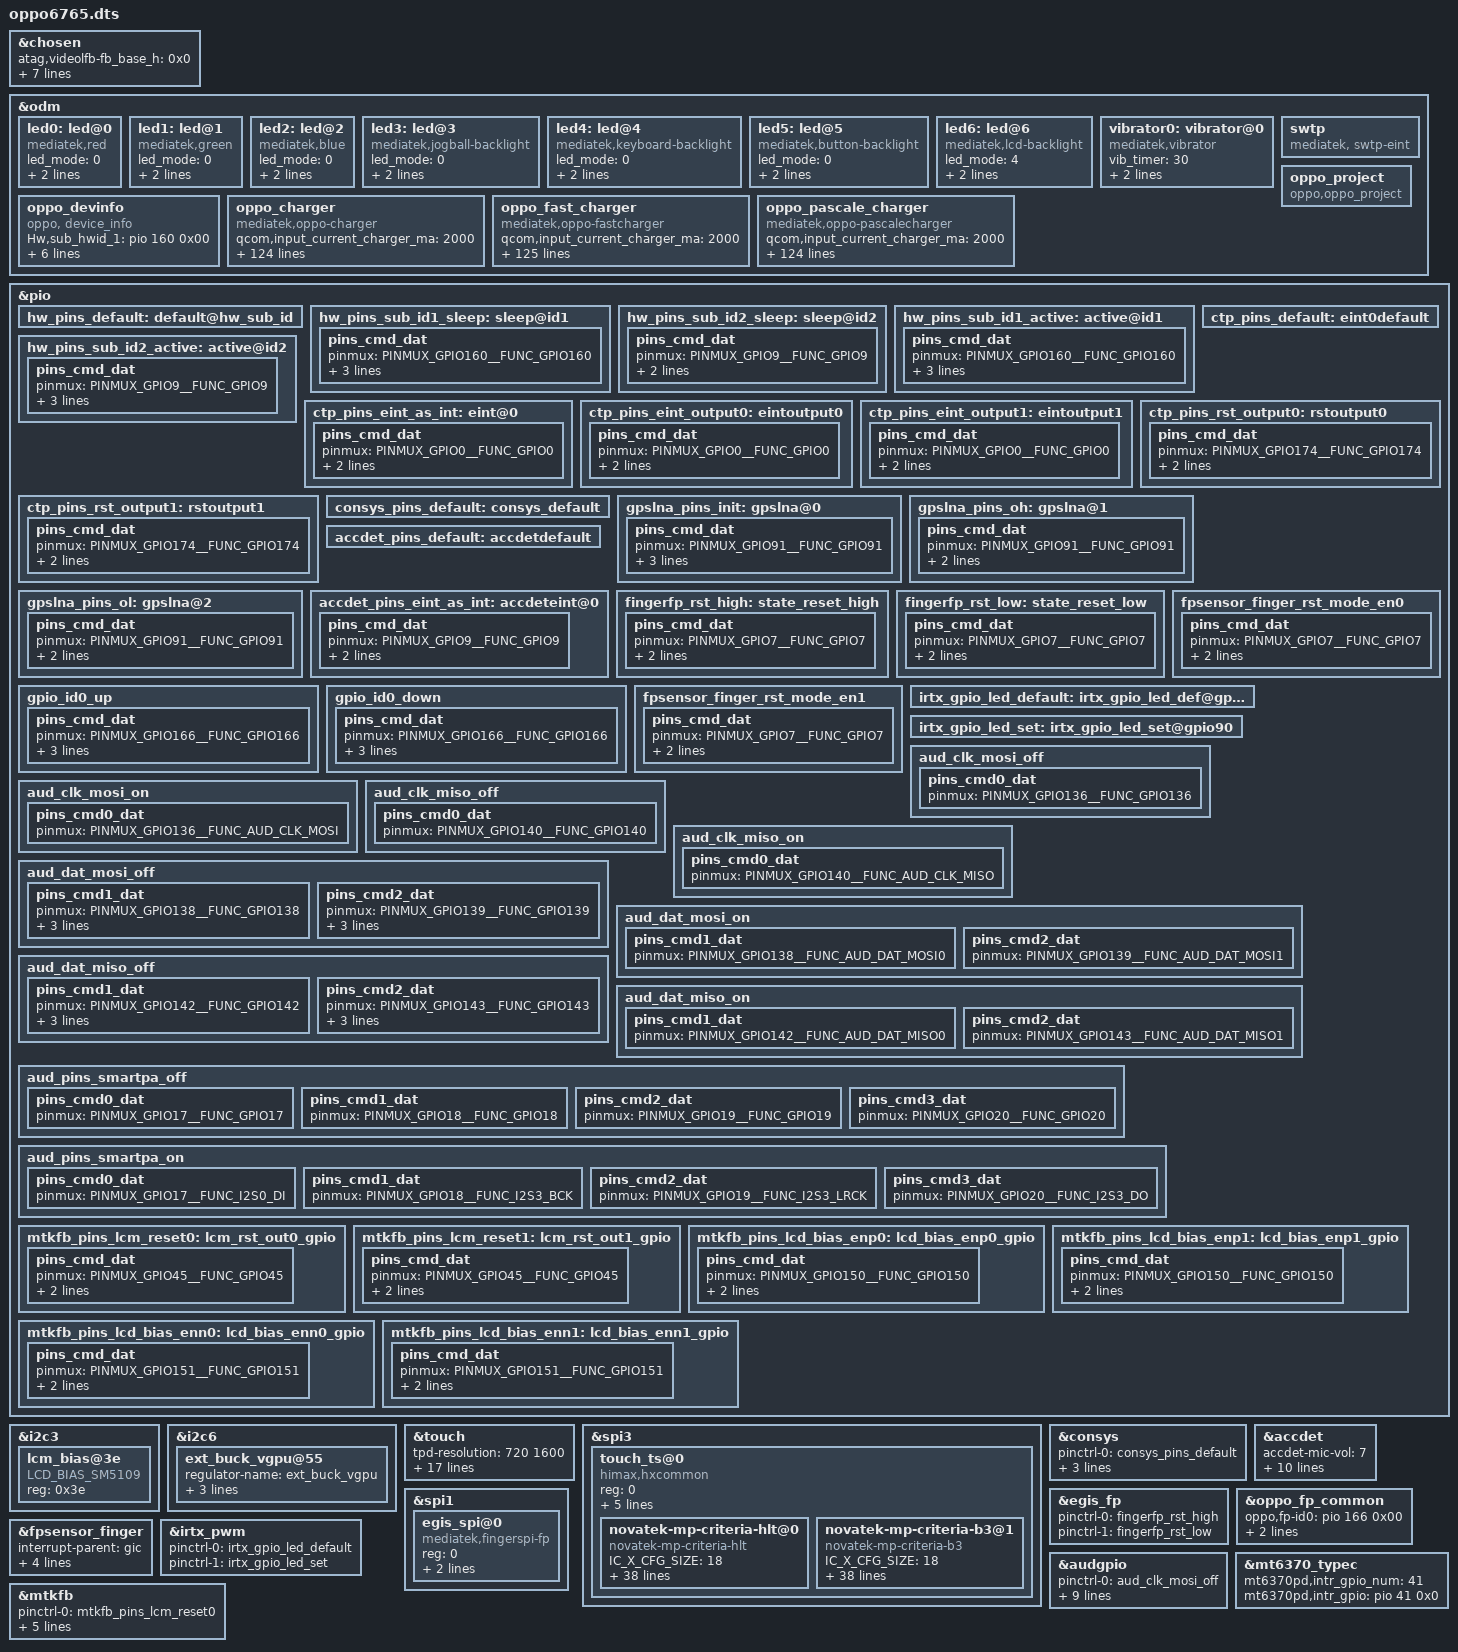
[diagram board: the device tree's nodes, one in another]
/*
 * Copyright (C) 2019 MediaTek Inc.
 *
 * This program is free software; you can redistribute it and/or modify
 * it under the terms of the GNU General Public License version 2 as
 * published by the Free Software Foundation.
 *
 * This program is distributed in the hope that it will be useful,
 * but WITHOUT ANY WARRANTY; without even the implied warranty of
 * MERCHANTABILITY or FITNESS FOR A PARTICULAR PURPOSE.
 * See http://www.gnu.org/licenses/gpl-2.0.html for more details.
 */

#include <dt-bindings/interrupt-controller/arm-gic.h>
#include <dt-bindings/interrupt-controller/irq.h>
#include <dt-bindings/pinctrl/mt6765-pinfunc.h>
#include <dt-bindings/clock/mt6765-clk.h>

/dts-v1/;
/plugin/;

/* chosen */
&chosen {

	/* fpga may has no lk, we need to specify display info here */
	/* fb buffer is reserved using this dts by memory node above */
	atag,videolfb-fb_base_h = <0x0>;
	atag,videolfb-fb_base_l = <0x5e605000>;
	atag,videolfb-islcmfound = <1>;
	/* because no lk, so lcm is not inited */
	atag,videolfb-islcm_inited = <0>;
	atag,videolfb-fps= <6000>;
	atag,videolfb-vramSize= <0x017bb000>;
	atag,videolfb-lcmname= "nt35695B_fhd_dsi_cmd_auo_rt5081_drv";
};

&odm {
	led0:led@0 {
		compatible = "mediatek,red";
		led_mode = <0>;
		data = <1>;
		pwm_config = <0 0 0 0 0>;
	};
	led1:led@1 {
		compatible = "mediatek,green";
		led_mode = <0>;
		data = <1>;
		pwm_config = <0 0 0 0 0>;
	};
	led2:led@2 {
		compatible = "mediatek,blue";
		led_mode = <0>;
		data = <1>;
		pwm_config = <0 0 0 0 0>;
	};
	led3:led@3 {
		compatible = "mediatek,jogball-backlight";
		led_mode = <0>;
		data = <1>;
		pwm_config = <0 0 0 0 0>;
	};
	led4:led@4 {
		compatible = "mediatek,keyboard-backlight";
		led_mode = <0>;
		data = <1>;
		pwm_config = <0 0 0 0 0>;
	};
	led5:led@5 {
		compatible = "mediatek,button-backlight";
		led_mode = <0>;
		data = <1>;
		pwm_config = <0 0 0 0 0>;
	};
	led6:led@6 {
		compatible = "mediatek,lcd-backlight";
		led_mode = <4>;
		data = <1>;
		pwm_config = <0 3 0 0 0>;
	};
	vibrator0:vibrator@0 {
		compatible = "mediatek,vibrator";
		/*
		vib_timer = <25>;
		vib_limit = <9>;
		vib_vol= <9>;
		*/
/* Tiancheng.Peng@ODM_WT.BSP.POWER 2020/04/09,add vibrator vol to 3V*/
		vib_timer = <30>;
		vib_limit = <0>;
		vib_vol= <11>;
	};
//#ifdef ODM_WT_EDIT
/*Xin.Kou@ODM_WT.NW.RF.swtp, 2020/04/08, Add for swtp, RF cable detect */
	swtp:swtp {
		compatible = "mediatek, swtp-eint";
	};
//#endif /*ODM_WT_EDIT*/
//#ifdef ODM_WT_EDIT
/* Haibo.Dong@ODM_WT.BSP.Storage.Emmc 2020/03/28,add oppo project framework*/
	oppo_project:oppo_project {
		compatible = "oppo,oppo_project";
	};
/* Haibo.Dong@ODM_WT.BSP.Storage.Emmc 2020/04/02,add oppo devinfo framework*/
	oppo_devinfo:oppo_devinfo {
		compatible = "oppo, device_info";
	};
//#endif /*ODM_WT_EDIT*/

//#ifdef ODM_WT_EDIT
/*Sidong.Zhao@ODM_WT.BSP.CHG 2019/11/4,add oppo charge framework*/
	oppo_charger: oppo_charger {
		compatible = "mediatek,oppo-charger";
		//pinctrl-names = "default", "charger_gpio_as_output_low", "charger_gpio_as_output_high", "ship_sleep", "ship_active", "shortc_active";
		//pinctrl-0 = <&charger_pins_default>;
		//pinctrl-1 = <&charger_pins_eint_output0>;
		//pinctrl-2 = <&charger_pins_eint_output1>;
		//pinctrl-3 = <&ship_sleep_gpio>;
		//pinctrl-4 = <&ship_active_gpio>;
		//pinctrl-5 = <&shortc_active_gpio>;

		//for oppo chg framework:
		qcom,input_current_charger_ma = <2000>;
		qcom,input_current_cdp_ma = <1500>;
		qcom,input_current_usb_ma = <500>;
		qcom,input_current_led_ma = <1200>;
		qcom,input_current_led_ma_forcmcc = <500>;
		qcom,input_current_camera_ma = <1200>;
		qcom,input_current_calling_ma = <1200>;
		
		qcom,input_current_led_ma_high = <1200>;
		qcom,input_current_led_ma_warm = <1500>;
		qcom,input_current_led_ma_normal = <2000>;

		qcom,led_high_bat_decidegc = <370>;
		qcom,led_warm_bat_decidegc = <350>;

		qcom,iterm_disabled = <0>;
		qcom,iterm_ma = <265>;
		qcom,recharge-mv = <115>;

		qcom,batt_capacity_mah = <5000>; /*typical capacity*/
		//qcom,batt_capacity_mah = <3900>; /*rated capacity*/

		qcom,removed_bat_decidegc = <190>;  /* < -19C */

		qcom,cold_bat_decidegc = <20>;  /* -2C ~ 0C */
		qcom,temp_cold_vfloat_mv = <3980>;
		qcom,temp_cold_fastchg_current_ma = <350>;

		qcom,little_cold_bat_decidegc = <0>;	/* 0C ~ 5C */
		qcom,temp_little_cold_vfloat_mv = <4435>;
		qcom,temp_little_cold_fastchg_current_ma_high = <650>;
		qcom,temp_little_cold_fastchg_current_ma_low = <650>;
		qcom,temp_little_cold_fastchg_current_ma = <650>;
		monet,temp_little_cold_usbchg_current_ma_high = <650>;
		monet,temp_little_cold_usbchg_current_ma_low = <650>;
		monet,temp_little_cold_usbchg_current_ma = <650>;

		qcom,cool_bat_decidegc = <50>;	/* 5C ~ 12C */
		qcom,temp_cool_vfloat_mv = <4435>;
		qcom,temp_cool_fastchg_current_ma_high = <1350>;
		qcom,temp_cool_fastchg_current_ma_low = <650>;
		monet,temp_cool_usbchg_current_ma_high = <650>;
		monet,temp_cool_usbchg_current_ma_low = <550>;

		qcom,little_cool_bat_decidegc = <120>;	/* 12C ~ 16C */
		qcom,temp_little_cool_vfloat_mv = <4435>;
		qcom,temp_little_cool_fastchg_current_ma = <2050>;
		monet,temp_little_cool_usbchg_current_ma = <550>;

		qcom,normal_bat_decidegc = <160>;	/* 16C ~ 45C */
		qcom,temp_normal_fastchg_current_ma = <2200>;
		monet,temp_normal_usbchg_current_ma = <550>;
		qcom,temp_normal_vfloat_mv = <4435>;

		qcom,warm_bat_decidegc = <440>;		/* 44C ~ 53C */ /*8pin Bat Vooc project need add 3 degree C*/
		qcom,temp_warm_vfloat_mv = <4130>;
		qcom,temp_warm_fastchg_current_ma = <1350>;
		monet,temp_warm_usbchg_current_ma = <550>;
		qcom,temp_warm_fastchg_current_ma_led_on = <500>;

		qcom,hot_bat_decidegc = <530>;  /* > 53C */

		qcom,non_standard_vfloat_mv = <3980>;
		qcom,non_standard_fastchg_current_ma = <512>;

		qcom,short_c_bat_cv_mv = <4330>;
		qcom,short_c_bat_vfloat_mv = <3800>;
		qcom,short_c_bat_fastchg_current_ma = <512>;
		qcom,short_c_bat_vfloat_sw_limit = <3750>;

		qcom,cold_vfloat_sw_limit = <3930>;
		qcom,little_cold_vfloat_sw_limit = <4380>;
		qcom,cool_vfloat_sw_limit = <4380>;
		qcom,little_cool_vfloat_sw_limit = <4380>;
		qcom,normal_vfloat_sw_limit = <4380>;
		qcom,warm_vfloat_sw_limit = <4080>;
		qcom,non_standard_vfloat_sw_limit = <3930>;

		qcom,max_chg_time_sec = <60000>;
		qcom,charger_hv_thr = <5800>;
		qcom,charger_recv_thr = <5800>;
		qcom,charger_lv_thr = <3400>;
		qcom,vbatt_full_thr = <4400>;
		qcom,vbatt_hv_thr = <4550>;

		qcom,vfloat_step_mv = <10>;
		qcom,non_standard_vfloat_over_sw_limit = <4000>;
		qcom,cold_vfloat_over_sw_limit = <4000>;
		qcom,little_cold_vfloat_over_sw_limit = <4450>;
		qcom,cool_vfloat_over_sw_limit = <4450>;
		qcom,little_cool_vfloat_over_sw_limit = <4450>;
		qcom,normal_vfloat_over_sw_limit = <4450>;
		qcom,warm_vfloat_over_sw_limit = <4150>;

		qcom,vbatt_power_off = <3300>;
		qcom,vbatt_soc_1 = <3410>;
		qcom,vooc_project = <0>;
		qcom,vbatt_num = <1>;

		qcom,normal_vterm_hw_inc = <150>;
		qcom,non_normal_vterm_hw_inc = <10>;

		qcom,ff1_normal_fastchg_ma = <1088>;
		qcom,ffc2_normal_fastchg_ma = <780>;/*16C~35c*/
		qcom,ffc2_temp_warm_decidegc = <350>;
		qcom,ffc2_warm_fastchg_ma = <840>;/*35C~40c*/
		qcom,ffc2_temp_high_decidegc = <400>;
		qcom,ffc2_temp_low_decidegc = <120>;
		qcom,ff1_exit_step_ma = <488>;
		qcom,ff1_warm_exit_step_ma = <418>;
		qcom,ffc2_exit_step_ma = <180>;
		qcom,ffc2_warm_exit_step_ma = <170>;

		qcom,ffc_normal_vfloat_sw_limit = <4430>;
		qcom,ffc_temp_normal_vfloat_mv = <4500>;
		qcom,ffc_normal_vfloat_over_sw_limit = <4500>;

		qcom,default_iterm_ma = <265>;
		qcom,default_temp_normal_fastchg_current_ma = <2200>;
		qcom,default_normal_vfloat_sw_limit = <4380>;
		qcom,default_temp_normal_vfloat_mv = <4435>;
		qcom,default_normal_vfloat_over_sw_limit = <4450>;

		//for 2nd chip:
		qcom,iterm_ma_2nd = <300>;
		qcom,recharge-mv_2nd = <121>;

		qcom,temp_little_cold_vfloat_mv_2nd = <4391>;	/* 0C ~ 5C */
		qcom,temp_cool_vfloat_mv_2nd = <4391>;	/* 5C ~ 12C */
		qcom,temp_little_cool_vfloat_mv_2nd = <4391>;	/* 12C ~ 16C */
		qcom,temp_normal_vfloat_mv_2nd = <4391>;	/* 16C ~ 45C */

		qcom,little_cold_vfloat_over_sw_limit_2nd = <4395>;
		qcom,cool_vfloat_over_sw_limit_2nd = <4395>;
		qcom,little_cool_vfloat_over_sw_limit_2nd = <4395>;
		qcom,normal_vfloat_over_sw_limit_2nd = <4395>;

		qcom,default_iterm_ma_2nd = <300>;
		qcom,default_temp_normal_vfloat_mv_2nd = <4391>;
		qcom,default_normal_vfloat_over_sw_limit_2nd = <4395>;

		//for control:
		//qcom,suspend_after_full;
		qcom,check_batt_full_by_sw;
		//qcom,external_gauge;
		qcom,chg_ctrl_by_calling;
		qcom,chg_ctrl_by_lcd;
		qcom,chg_ctrl_by_camera;
		qcom,sw_vfloat_over_protect_enable;
		//qcom,ffc_support;

		//GPIO config:
		//qcom,chargerid_switch-gpio = <&pio 97 0x00>;
		//qcom,ship-gpio = <&pio 155 0x00>;
		//qcom,shortc-gpio = <&pio 77 0x00>;
	};

oppo_fast_charger: oppo_fast_charger {
		compatible = "mediatek,oppo-fastcharger";
		//pinctrl-names = "default", "charger_gpio_as_output_low", "charger_gpio_as_output_high", "ship_sleep", "ship_active", "shortc_active";
		//pinctrl-0 = <&charger_pins_default>;
		//pinctrl-1 = <&charger_pins_eint_output0>;
		//pinctrl-2 = <&charger_pins_eint_output1>;
		//pinctrl-3 = <&ship_sleep_gpio>;
		//pinctrl-4 = <&ship_active_gpio>;
		//pinctrl-5 = <&shortc_active_gpio>;

		//for oppo chg framework:
		qcom,input_current_charger_ma = <2000>;
		qcom,input_current_cdp_ma = <1500>;
		qcom,input_current_usb_ma = <500>;
		qcom,input_current_led_ma = <1200>;
		qcom,input_current_led_ma_forcmcc = <500>;
		qcom,input_current_camera_ma = <1200>;
		qcom,input_current_calling_ma = <1200>;

		qcom,input_current_led_ma_high = <1000>;
		qcom,input_current_led_ma_warm = <1500>;
		qcom,input_current_led_ma_normal = <2000>;

		qcom,led_high_bat_decidegc = <370>;
		qcom,led_warm_bat_decidegc = <340>;

		qcom,iterm_disabled = <0>;
		qcom,iterm_ma = <300>;
		qcom,recharge-mv = <115>;

		qcom,batt_capacity_mah = <5000>; /*typical capacity*/
		//qcom,batt_capacity_mah = <3900>; /*rated capacity*/

		qcom,removed_bat_decidegc = <190>;  /* < -19C */

		qcom,cold_bat_decidegc = <20>;  /* -2C ~ 0C */
		qcom,temp_cold_vfloat_mv = <3980>;
		qcom,temp_cold_fastchg_current_ma = <350>;

		qcom,little_cold_bat_decidegc = <0>;	/* 0C ~ 5C */
		qcom,temp_little_cold_vfloat_mv = <4435>;
		qcom,temp_little_cold_fastchg_current_ma_high = <800>;
		qcom,temp_little_cold_fastchg_current_ma_low = <800>;
		qcom,temp_little_cold_fastchg_current_ma = <800>;
		monet,temp_little_cold_usbchg_current_ma_high = <650>;
		monet,temp_little_cold_usbchg_current_ma_low = <650>;
		monet,temp_little_cold_usbchg_current_ma = <650>;

		qcom,cool_bat_decidegc = <50>;	/* 5C ~ 12C */
		qcom,temp_cool_vfloat_mv = <4435>;
		qcom,temp_cool_fastchg_current_ma_high = <1650>;
		qcom,temp_cool_fastchg_current_ma_low = <800>;
		monet,temp_cool_usbchg_current_ma_high = <650>;
		monet,temp_cool_usbchg_current_ma_low = <550>;

		qcom,little_cool_bat_decidegc = <120>;	/* 12C ~ 16C */
		qcom,temp_little_cool_vfloat_mv = <4435>;
		qcom,temp_little_cool_fastchg_current_ma = <2050>;
		monet,temp_little_cool_usbchg_current_ma = <550>;

		qcom,normal_bat_decidegc = <160>;	/* 16C ~ 45C */
		qcom,temp_normal_fastchg_current_ma = <2200>;
		monet,temp_normal_usbchg_current_ma = <550>;
		qcom,temp_normal_vfloat_mv = <4435>;

		qcom,warm_bat_decidegc = <450>;		/* 45C ~ 53C */ /*8pin Bat Vooc project need add 3 degree C*/
		qcom,temp_warm_vfloat_mv = <4130>;
		qcom,temp_warm_fastchg_current_ma = <1650>;
		monet,temp_warm_usbchg_current_ma = <550>;
		qcom,temp_warm_fastchg_current_ma_led_on = <500>;

		qcom,hot_bat_decidegc = <530>;  /* > 53C */

		qcom,non_standard_vfloat_mv = <3980>;
		qcom,non_standard_fastchg_current_ma = <512>;

		qcom,short_c_bat_cv_mv = <4330>;
		qcom,short_c_bat_vfloat_mv = <3800>;
		qcom,short_c_bat_fastchg_current_ma = <512>;
		qcom,short_c_bat_vfloat_sw_limit = <3750>;

		qcom,cold_vfloat_sw_limit = <3930>;
		qcom,little_cold_vfloat_sw_limit = <4380>;
		qcom,cool_vfloat_sw_limit = <4380>;
		qcom,little_cool_vfloat_sw_limit = <4380>;
		qcom,normal_vfloat_sw_limit = <4380>;
		qcom,warm_vfloat_sw_limit = <4080>;
		qcom,non_standard_vfloat_sw_limit = <3930>;

		qcom,max_chg_time_sec = <72000>;
		qcom,charger_hv_thr = <9800>;
		qcom,charger_recv_thr = <9800>;
		qcom,charger_lv_thr = <3400>;
		qcom,vbatt_full_thr = <4400>;
		qcom,vbatt_hv_thr = <4550>;

		qcom,vfloat_step_mv = <10>;
		qcom,non_standard_vfloat_over_sw_limit = <4000>;
		qcom,cold_vfloat_over_sw_limit = <4000>;
		qcom,little_cold_vfloat_over_sw_limit = <4450>;
		qcom,cool_vfloat_over_sw_limit = <4450>;
		qcom,little_cool_vfloat_over_sw_limit = <4450>;
		qcom,normal_vfloat_over_sw_limit = <4450>;
		qcom,warm_vfloat_over_sw_limit = <4150>;

		qcom,vbatt_power_off = <3300>;
		qcom,vbatt_soc_1 = <3410>;
		qcom,vooc_project = <0>;
		qcom,vbatt_num = <1>;

		qcom,normal_vterm_hw_inc = <150>;
		qcom,non_normal_vterm_hw_inc = <10>;

		qcom,ff1_normal_fastchg_ma = <1088>;
		qcom,ffc2_normal_fastchg_ma = <780>;/*16C~35c*/
		qcom,ffc2_temp_warm_decidegc = <350>;
		qcom,ffc2_warm_fastchg_ma = <840>;/*35C~40c*/
		qcom,ffc2_temp_high_decidegc = <400>;
		qcom,ffc2_temp_low_decidegc = <120>;
		qcom,ff1_exit_step_ma = <488>;
		qcom,ff1_warm_exit_step_ma = <418>;
		qcom,ffc2_exit_step_ma = <180>;
		qcom,ffc2_warm_exit_step_ma = <170>;

		qcom,ffc_normal_vfloat_sw_limit = <4430>;
		qcom,ffc_temp_normal_vfloat_mv = <4500>;
		qcom,ffc_normal_vfloat_over_sw_limit = <4500>;

		qcom,default_iterm_ma = <300>;
		qcom,default_temp_normal_fastchg_current_ma = <2200>;
		qcom,default_normal_vfloat_sw_limit = <4380>;
		qcom,default_temp_normal_vfloat_mv = <4435>;
		qcom,default_normal_vfloat_over_sw_limit = <4450>;

		//for 2nd chip:
		qcom,iterm_ma_2nd = <300>;
		qcom,recharge-mv_2nd = <121>;

		qcom,temp_little_cold_vfloat_mv_2nd = <4391>;	/* 0C ~ 5C */
		qcom,temp_cool_vfloat_mv_2nd = <4391>;	/* 5C ~ 12C */
		qcom,temp_little_cool_vfloat_mv_2nd = <4391>;	/* 12C ~ 16C */
		qcom,temp_normal_vfloat_mv_2nd = <4391>;	/* 16C ~ 45C */

		qcom,little_cold_vfloat_over_sw_limit_2nd = <4395>;
		qcom,cool_vfloat_over_sw_limit_2nd = <4395>;
		qcom,little_cool_vfloat_over_sw_limit_2nd = <4395>;
		qcom,normal_vfloat_over_sw_limit_2nd = <4395>;

		qcom,default_iterm_ma_2nd = <300>;
		qcom,default_temp_normal_vfloat_mv_2nd = <4391>;
		qcom,default_normal_vfloat_over_sw_limit_2nd = <4395>;

		//for control:
		//qcom,suspend_after_full;
		qcom,check_batt_full_by_sw;
		//qcom,external_gauge;
		qcom,chg_ctrl_by_calling;
		qcom,chg_ctrl_by_lcd;
		qcom,chg_ctrl_by_camera;
		qcom,sw_vfloat_over_protect_enable;
		//qcom,ffc_support;

		//GPIO config:
		//qcom,chargerid_switch-gpio = <&pio 97 0x00>;
		//qcom,ship-gpio = <&pio 155 0x00>;
		//qcom,shortc-gpio = <&pio 77 0x00>;

		qcom,vbatt_pdqc_to_5v_thr = <4420>;
		status = "okay";
	};

oppo_pascale_charger: oppo_pascale_charger {
		compatible = "mediatek,oppo-pascalecharger";
		//pinctrl-names = "default", "charger_gpio_as_output_low", "charger_gpio_as_output_high", "ship_sleep", "ship_active", "shortc_active";
		//pinctrl-0 = <&charger_pins_default>;
		//pinctrl-1 = <&charger_pins_eint_output0>;
		//pinctrl-2 = <&charger_pins_eint_output1>;
		//pinctrl-3 = <&ship_sleep_gpio>;
		//pinctrl-4 = <&ship_active_gpio>;
		//pinctrl-5 = <&shortc_active_gpio>;

		//for oppo chg framework:
		qcom,input_current_charger_ma = <2000>;
		qcom,input_current_cdp_ma = <1500>;
		qcom,input_current_usb_ma = <500>;
		qcom,input_current_led_ma = <1200>;
		qcom,input_current_led_ma_forcmcc = <500>;
		qcom,input_current_camera_ma = <1200>;
		qcom,input_current_calling_ma = <1200>;

		qcom,input_current_led_ma_high = <1000>;
		qcom,input_current_led_ma_warm = <1500>;
		qcom,input_current_led_ma_normal = <2000>;

		qcom,led_high_bat_decidegc = <370>;
		qcom,led_warm_bat_decidegc = <340>;

		qcom,iterm_disabled = <0>;
		qcom,iterm_ma = <300>;
		qcom,recharge-mv = <115>;

		qcom,batt_capacity_mah = <6000>; /*typical capacity*/
		//qcom,batt_capacity_mah = <3900>; /*rated capacity*/

		qcom,removed_bat_decidegc = <190>;  /* < -19C */

		qcom,cold_bat_decidegc = <20>;  /* -2C ~ 0C */
		qcom,temp_cold_vfloat_mv = <3980>;
		qcom,temp_cold_fastchg_current_ma = <350>;

		qcom,little_cold_bat_decidegc = <0>;	/* 0C ~ 5C */
		qcom,temp_little_cold_vfloat_mv = <4435>;
		qcom,temp_little_cold_fastchg_current_ma_high = <800>;
		qcom,temp_little_cold_fastchg_current_ma_low = <800>;
		qcom,temp_little_cold_fastchg_current_ma = <800>;
		monet,temp_little_cold_usbchg_current_ma_high = <650>;
		monet,temp_little_cold_usbchg_current_ma_low = <650>;
		monet,temp_little_cold_usbchg_current_ma = <650>;

		qcom,cool_bat_decidegc = <50>;	/* 5C ~ 12C */
		qcom,temp_cool_vfloat_mv = <4435>;
		qcom,temp_cool_fastchg_current_ma_high = <1650>;
		qcom,temp_cool_fastchg_current_ma_low = <800>;
		monet,temp_cool_usbchg_current_ma_high = <650>;
		monet,temp_cool_usbchg_current_ma_low = <550>;

		qcom,little_cool_bat_decidegc = <120>;	/* 12C ~ 16C */
		qcom,temp_little_cool_vfloat_mv = <4435>;
		qcom,temp_little_cool_fastchg_current_ma = <2050>;
		monet,temp_little_cool_usbchg_current_ma = <550>;

		qcom,normal_bat_decidegc = <160>;	/* 16C ~ 45C */
		qcom,temp_normal_fastchg_current_ma = <2200>;
		monet,temp_normal_usbchg_current_ma = <550>;
		qcom,temp_normal_vfloat_mv = <4435>;

		qcom,warm_bat_decidegc = <450>;		/* 45C ~ 53C */ /*8pin Bat Vooc project need add 3 degree C*/
		qcom,temp_warm_vfloat_mv = <4130>;
		qcom,temp_warm_fastchg_current_ma = <1650>;
		monet,temp_warm_usbchg_current_ma = <550>;
		qcom,temp_warm_fastchg_current_ma_led_on = <500>;

		qcom,hot_bat_decidegc = <530>;  /* > 53C */

		qcom,non_standard_vfloat_mv = <3980>;
		qcom,non_standard_fastchg_current_ma = <512>;

		qcom,short_c_bat_cv_mv = <4330>;
		qcom,short_c_bat_vfloat_mv = <3800>;
		qcom,short_c_bat_fastchg_current_ma = <512>;
		qcom,short_c_bat_vfloat_sw_limit = <3750>;

		qcom,cold_vfloat_sw_limit = <3930>;
		qcom,little_cold_vfloat_sw_limit = <4380>;
		qcom,cool_vfloat_sw_limit = <4380>;
		qcom,little_cool_vfloat_sw_limit = <4380>;
		qcom,normal_vfloat_sw_limit = <4380>;
		qcom,warm_vfloat_sw_limit = <4080>;
		qcom,non_standard_vfloat_sw_limit = <3930>;

		qcom,max_chg_time_sec = <72000>;
		qcom,charger_hv_thr = <9800>;
		qcom,charger_recv_thr = <9800>;
		qcom,charger_lv_thr = <3400>;
		qcom,vbatt_full_thr = <4400>;
		qcom,vbatt_hv_thr = <4550>;

		qcom,vfloat_step_mv = <10>;
		qcom,non_standard_vfloat_over_sw_limit = <4000>;
		qcom,cold_vfloat_over_sw_limit = <4000>;
		qcom,little_cold_vfloat_over_sw_limit = <4450>;
		qcom,cool_vfloat_over_sw_limit = <4450>;
		qcom,little_cool_vfloat_over_sw_limit = <4450>;
		qcom,normal_vfloat_over_sw_limit = <4450>;
		qcom,warm_vfloat_over_sw_limit = <4150>;

		qcom,vbatt_power_off = <3300>;
		qcom,vbatt_soc_1 = <3410>;
		qcom,vooc_project = <0>;
		qcom,vbatt_num = <1>;

		qcom,normal_vterm_hw_inc = <150>;
		qcom,non_normal_vterm_hw_inc = <10>;

		qcom,ff1_normal_fastchg_ma = <1088>;
		qcom,ffc2_normal_fastchg_ma = <780>;/*16C~35c*/
		qcom,ffc2_temp_warm_decidegc = <350>;
		qcom,ffc2_warm_fastchg_ma = <840>;/*35C~40c*/
		qcom,ffc2_temp_high_decidegc = <400>;
		qcom,ffc2_temp_low_decidegc = <120>;
		qcom,ff1_exit_step_ma = <488>;
		qcom,ff1_warm_exit_step_ma = <418>;
		qcom,ffc2_exit_step_ma = <180>;
		qcom,ffc2_warm_exit_step_ma = <170>;

		qcom,ffc_normal_vfloat_sw_limit = <4430>;
		qcom,ffc_temp_normal_vfloat_mv = <4500>;
		qcom,ffc_normal_vfloat_over_sw_limit = <4500>;

		qcom,default_iterm_ma = <300>;
		qcom,default_temp_normal_fastchg_current_ma = <2200>;
		qcom,default_normal_vfloat_sw_limit = <4380>;
		qcom,default_temp_normal_vfloat_mv = <4435>;
		qcom,default_normal_vfloat_over_sw_limit = <4450>;

		//for 2nd chip:
		qcom,iterm_ma_2nd = <300>;
		qcom,recharge-mv_2nd = <121>;

		qcom,temp_little_cold_vfloat_mv_2nd = <4391>;	/* 0C ~ 5C */
		qcom,temp_cool_vfloat_mv_2nd = <4391>;	/* 5C ~ 12C */
		qcom,temp_little_cool_vfloat_mv_2nd = <4391>;	/* 12C ~ 16C */
		qcom,temp_normal_vfloat_mv_2nd = <4391>;	/* 16C ~ 45C */

		qcom,little_cold_vfloat_over_sw_limit_2nd = <4395>;
		qcom,cool_vfloat_over_sw_limit_2nd = <4395>;
		qcom,little_cool_vfloat_over_sw_limit_2nd = <4395>;
		qcom,normal_vfloat_over_sw_limit_2nd = <4395>;

		qcom,default_iterm_ma_2nd = <300>;
		qcom,default_temp_normal_vfloat_mv_2nd = <4391>;
		qcom,default_normal_vfloat_over_sw_limit_2nd = <4395>;

		//for control:
		//qcom,suspend_after_full;
		qcom,check_batt_full_by_sw;
		//qcom,external_gauge;
		qcom,chg_ctrl_by_calling;
		qcom,chg_ctrl_by_lcd;
		qcom,chg_ctrl_by_camera;
		qcom,sw_vfloat_over_protect_enable;
		//qcom,ffc_support;

		//GPIO config:
		//qcom,chargerid_switch-gpio = <&pio 97 0x00>;
		//qcom,ship-gpio = <&pio 155 0x00>;
		//qcom,shortc-gpio = <&pio 77 0x00>;
		status = "okay";
	};
//#endif /*ODM_WT_EDIT*/
};
//#ifdef ODM_WT_EDIT
/* Haibo.Dong@ODM_WT.BSP.Storage.Emmc 2020/04/04,add sub_id match*/
&oppo_devinfo {
	Hw,sub_hwid_1 = <&pio 160 0x00>;
	Hw,sub_hwid_2 = <&pio 9 0x00>;
	pinctrl-names = "default", "hw_sub_id_sleep", "hw_sub_id_active";
	pinctrl-0 = <&hw_pins_default>;
	pinctrl-1 = <&hw_pins_sub_id1_sleep &hw_pins_sub_id2_sleep>;
	pinctrl-2 = <&hw_pins_sub_id1_active &hw_pins_sub_id2_active>;
};

&pio {
	hw_pins_default:default@hw_sub_id {
	};

	hw_pins_sub_id1_sleep:sleep@id1 {
			pins_cmd_dat {
				pinmux = <PINMUX_GPIO160__FUNC_GPIO160>;
				slew-rate = <0>;
				bias-pull-down = <00>;
				input-enable;
			};
	};

	hw_pins_sub_id2_sleep:sleep@id2 {
			pins_cmd_dat {
				pinmux = <PINMUX_GPIO9__FUNC_GPIO9>;
				bias-pull-down = <00>;
				input-enable;
			};
	};

	hw_pins_sub_id1_active:active@id1 {
		pins_cmd_dat {
			pinmux = <PINMUX_GPIO160__FUNC_GPIO160>;
			slew-rate = <0>;
			input-enable;
			bias-disable;
		};
	};
	hw_pins_sub_id2_active:active@id2 {
		pins_cmd_dat {
			pinmux = <PINMUX_GPIO9__FUNC_GPIO9>;
			slew-rate = <0>;
			input-enable;
			bias-disable;
		};
	};
};
//#endif /*ODM_WT_EDIT*/

&i2c3 {
		lcm_bias@3e{
               compatible = "LCD_BIAS_SM5109","LCD_BIAS_OCP2130";
               reg = <0x3e>;
               status = "okay";
	};
};

&i2c6 {
	ext_buck_vgpu@55 {
		regulator-name ="ext_buck_vgpu";
		regulator-min-microvolt = <300000>;
		regulator-max-microvolt = <1300000>;
		vsel_pin = <2>;
	};
};
/* TOUCH start */
&touch {
	tpd-resolution = <720 1600>;
	use-tpd-button = <0>;
	tpd-key-num = <3>;
	tpd-key-local= <139 172 158 0>;
	tpd-key-dim-local = <90 883 100 40 230
				 883 100 40 370 883 100 40 0 0 0 0>;
	tpd-max-touch-num = <5>;
	tpd-filter-enable = <0>;
	tpd-filter-pixel-density = <146>;
	tpd-filter-custom-prameters = <0 0 0 0 0 0 0 0 0 0 0 0>;
	tpd-filter-custom-speed = <0 0 0>;
	pinctrl-names = "default", "state_eint_as_int", "state_eint_output0",
		"state_eint_output1", "state_rst_output0", "state_rst_output1";
	pinctrl-0 = <&ctp_pins_default>;
	pinctrl-1 = <&ctp_pins_eint_as_int>;
	pinctrl-2 = <&ctp_pins_eint_output0>;
	pinctrl-3 = <&ctp_pins_eint_output1>;
	pinctrl-4 = <&ctp_pins_rst_output0>;
	pinctrl-5 = <&ctp_pins_rst_output1>;
	status = "okay";
};
&pio {
	ctp_pins_default: eint0default {
	};
	ctp_pins_eint_as_int: eint@0 {
		pins_cmd_dat {
			pinmux = <PINMUX_GPIO0__FUNC_GPIO0>;
			slew-rate = <0>;
			bias-disable;
		};
	};
	ctp_pins_eint_output0: eintoutput0 {
		pins_cmd_dat {
			pinmux = <PINMUX_GPIO0__FUNC_GPIO0>;
			slew-rate = <1>;
			output-low;
		};
	};
	ctp_pins_eint_output1: eintoutput1 {
		pins_cmd_dat {
			pinmux = <PINMUX_GPIO0__FUNC_GPIO0>;
			slew-rate = <1>;
			output-high;
		};
	};
	ctp_pins_rst_output0: rstoutput0 {
		pins_cmd_dat {
			pinmux = <PINMUX_GPIO174__FUNC_GPIO174>;
			slew-rate = <1>;
			output-low;
		};
	};
	ctp_pins_rst_output1: rstoutput1 {
		pins_cmd_dat {
			pinmux = <PINMUX_GPIO174__FUNC_GPIO174>;
			slew-rate = <1>;
			output-high;
		};
	};
};
//#ifdef ODM_WT_EDIT
//#Yize.Zhang@ODM_WT.BSP.Touchscreen.Base,2020/03/27,bringup add for xl/hlt/txd touchscreen mould dts config.
&spi3 {
    #address-cells = <1>;
    #size-cells = <0>;

    touch_ts@0 {
        reg = <0>;
        compatible = "himax,hxcommon","ilitek,ilitek-ts-spi","novatek,NVT-ts-spi";
        spi-max-frequency = <9600000>;
        status = "okay";
        /* touch spi config */
		novatek,reset-gpio = <&pio 174 0x00>;
		novatek,irq-gpio = <&pio 0 0x2002>;

		/* 672 */
		//novatek,swrst-n8-addr = <0x01F01A>;

		/* 672A, 525B */
		novatek,swrst-n8-addr = <0x03F0FE>;

		/* MP */
		novatek,mp-support-dt;

		novatek-mp-criteria-hlt@0 {
			#address-cells = <1>;
			#size-cells = <0>;
			compatible = "novatek-mp-criteria-hlt";

			/* MP Config */
			IC_X_CFG_SIZE = <18>;
			IC_Y_CFG_SIZE = <32>;
			IC_KEY_CFG_SIZE = <4>;
			X_Channel = <18>;
			Y_Channel = <32>;
			AIN_X = <0 1 2 3 4 5 6 7 8 9 10 11 12 13 14 15 16 17>;
			AIN_Y = <0 1 2 3 4 5 6 7 8 9 10 11 12 13 14 15 16 17 18 19
								20 21 22 23 24 25 26 27 28 29 30 31>;
			AIN_KEY = <0 1 2 0xFF>;

			/* MP Criteria */
			PS_Config_Lmt_Short_Rawdata_P = <
				14008 14008 14008 14008 14008 14008 14008 14008 14008 14008 14008 14008 14008 14008 14008 14008 14008 14008
				14008 14008 14008 14008 14008 14008 14008 14008 14008 14008 14008 14008 14008 14008 14008 14008 14008 14008
				14008 14008 14008 14008 14008 14008 14008 14008 14008 14008 14008 14008 14008 14008 14008 14008 14008 14008
				14008 14008 14008 14008 14008 14008 14008 14008 14008 14008 14008 14008 14008 14008 14008 14008 14008 14008
				14008 14008 14008 14008 14008 14008 14008 14008 14008 14008 14008 14008 14008 14008 14008 14008 14008 14008
				14008 14008 14008 14008 14008 14008 14008 14008 14008 14008 14008 14008 14008 14008 14008 14008 14008 14008
				14008 14008 14008 14008 14008 14008 14008 14008 14008 14008 14008 14008 14008 14008 14008 14008 14008 14008
				14008 14008 14008 14008 14008 14008 14008 14008 14008 14008 14008 14008 14008 14008 14008 14008 14008 14008
				14008 14008 14008 14008 14008 14008 14008 14008 14008 14008 14008 14008 14008 14008 14008 14008 14008 14008
				14008 14008 14008 14008 14008 14008 14008 14008 14008 14008 14008 14008 14008 14008 14008 14008 14008 14008
				14008 14008 14008 14008 14008 14008 14008 14008 14008 14008 14008 14008 14008 14008 14008 14008 14008 14008
				14008 14008 14008 14008 14008 14008 14008 14008 14008 14008 14008 14008 14008 14008 14008 14008 14008 14008
				14008 14008 14008 14008 14008 14008 14008 14008 14008 14008 14008 14008 14008 14008 14008 14008 14008 14008
				14008 14008 14008 14008 14008 14008 14008 14008 14008 14008 14008 14008 14008 14008 14008 14008 14008 14008
				14008 14008 14008 14008 14008 14008 14008 14008 14008 14008 14008 14008 14008 14008 14008 14008 14008 14008
				14008 14008 14008 14008 14008 14008 14008 14008 14008 14008 14008 14008 14008 14008 14008 14008 14008 14008
				14008 14008 14008 14008 14008 14008 14008 14008 14008 14008 14008 14008 14008 14008 14008 14008 14008 14008
				14008 14008 14008 14008 14008 14008 14008 14008 14008 14008 14008 14008 14008 14008 14008 14008 14008 14008
				14008 14008 14008 14008 14008 14008 14008 14008 14008 14008 14008 14008 14008 14008 14008 14008 14008 14008
				14008 14008 14008 14008 14008 14008 14008 14008 14008 14008 14008 14008 14008 14008 14008 14008 14008 14008
				14008 14008 14008 14008 14008 14008 14008 14008 14008 14008 14008 14008 14008 14008 14008 14008 14008 14008
				14008 14008 14008 14008 14008 14008 14008 14008 14008 14008 14008 14008 14008 14008 14008 14008 14008 14008
				14008 14008 14008 14008 14008 14008 14008 14008 14008 14008 14008 14008 14008 14008 14008 14008 14008 14008
				14008 14008 14008 14008 14008 14008 14008 14008 14008 14008 14008 14008 14008 14008 14008 14008 14008 14008
				14008 14008 14008 14008 14008 14008 14008 14008 14008 14008 14008 14008 14008 14008 14008 14008 14008 14008
				14008 14008 14008 14008 14008 14008 14008 14008 14008 14008 14008 14008 14008 14008 14008 14008 14008 14008
				14008 14008 14008 14008 14008 14008 14008 14008 14008 14008 14008 14008 14008 14008 14008 14008 14008 14008
				14008 14008 14008 14008 14008 14008 14008 14008 14008 14008 14008 14008 14008 14008 14008 14008 14008 14008
				14008 14008 14008 14008 14008 14008 14008 14008 14008 14008 14008 14008 14008 14008 14008 14008 14008 14008
				14008 14008 14008 14008 14008 14008 14008 14008 14008 14008 14008 14008 14008 14008 14008 14008 14008 14008
				14008 14008 14008 14008 14008 14008 14008 14008 14008 14008 14008 14008 14008 14008 14008 14008 14008 14008
				14008 14008 14008 14008 14008 14008 14008 14008 14008 14008 14008 14008 14008 14008 14008 14008 14008 14008
				>;

			PS_Config_Lmt_Short_Rawdata_N = <
				11376 11376 11376 11376 11376 11376 11376 11376 11376 11376 11376 11376 11376 11376 11376 11376 11376 11376
				11376 11376 11376 11376 11376 11376 11376 11376 11376 11376 11376 11376 11376 11376 11376 11376 11376 11376
				11376 11376 11376 11376 11376 11376 11376 11376 11376 11376 11376 11376 11376 11376 11376 11376 11376 11376
				11376 11376 11376 11376 11376 11376 11376 11376 11376 11376 11376 11376 11376 11376 11376 11376 11376 11376
				11376 11376 11376 11376 11376 11376 11376 11376 11376 11376 11376 11376 11376 11376 11376 11376 11376 11376
				11376 11376 11376 11376 11376 11376 11376 11376 11376 11376 11376 11376 11376 11376 11376 11376 11376 11376
				11376 11376 11376 11376 11376 11376 11376 11376 11376 11376 11376 11376 11376 11376 11376 11376 11376 11376
				11376 11376 11376 11376 11376 11376 11376 11376 11376 11376 11376 11376 11376 11376 11376 11376 11376 11376
				11376 11376 11376 11376 11376 11376 11376 11376 11376 11376 11376 11376 11376 11376 11376 11376 11376 11376
				11376 11376 11376 11376 11376 11376 11376 11376 11376 11376 11376 11376 11376 11376 11376 11376 11376 11376
				11376 11376 11376 11376 11376 11376 11376 11376 11376 11376 11376 11376 11376 11376 11376 11376 11376 11376
				11376 11376 11376 11376 11376 11376 11376 11376 11376 11376 11376 11376 11376 11376 11376 11376 11376 11376
				11376 11376 11376 11376 11376 11376 11376 11376 11376 11376 11376 11376 11376 11376 11376 11376 11376 11376
				11376 11376 11376 11376 11376 11376 11376 11376 11376 11376 11376 11376 11376 11376 11376 11376 11376 11376
				11376 11376 11376 11376 11376 11376 11376 11376 11376 11376 11376 11376 11376 11376 11376 11376 11376 11376
				11376 11376 11376 11376 11376 11376 11376 11376 11376 11376 11376 11376 11376 11376 11376 11376 11376 11376
				11376 11376 11376 11376 11376 11376 11376 11376 11376 11376 11376 11376 11376 11376 11376 11376 11376 11376
				11376 11376 11376 11376 11376 11376 11376 11376 11376 11376 11376 11376 11376 11376 11376 11376 11376 11376
				11376 11376 11376 11376 11376 11376 11376 11376 11376 11376 11376 11376 11376 11376 11376 11376 11376 11376
				11376 11376 11376 11376 11376 11376 11376 11376 11376 11376 11376 11376 11376 11376 11376 11376 11376 11376
				11376 11376 11376 11376 11376 11376 11376 11376 11376 11376 11376 11376 11376 11376 11376 11376 11376 11376
				11376 11376 11376 11376 11376 11376 11376 11376 11376 11376 11376 11376 11376 11376 11376 11376 11376 11376
				11376 11376 11376 11376 11376 11376 11376 11376 11376 11376 11376 11376 11376 11376 11376 11376 11376 11376
				11376 11376 11376 11376 11376 11376 11376 11376 11376 11376 11376 11376 11376 11376 11376 11376 11376 11376
				11376 11376 11376 11376 11376 11376 11376 11376 11376 11376 11376 11376 11376 11376 11376 11376 11376 11376
				11376 11376 11376 11376 11376 11376 11376 11376 11376 11376 11376 11376 11376 11376 11376 11376 11376 11376
				11376 11376 11376 11376 11376 11376 11376 11376 11376 11376 11376 11376 11376 11376 11376 11376 11376 11376
				11376 11376 11376 11376 11376 11376 11376 11376 11376 11376 11376 11376 11376 11376 11376 11376 11376 11376
				11376 11376 11376 11376 11376 11376 11376 11376 11376 11376 11376 11376 11376 11376 11376 11376 11376 11376
				11376 11376 11376 11376 11376 11376 11376 11376 11376 11376 11376 11376 11376 11376 11376 11376 11376 11376
				11376 11376 11376 11376 11376 11376 11376 11376 11376 11376 11376 11376 11376 11376 11376 11376 11376 11376
				11376 11376 11376 11376 11376 11376 11376 11376 11376 11376 11376 11376 11376 11376 11376 11376 11376 11376
				>;

			PS_Config_Lmt_Open_Rawdata_P = <
				3186 3204 3207 3229 3257 3218 3193 3271 65535 65535 3161 3088 3123 3166 3214 3273 3294 3238
				2919 2937 2980 3040 3098 3089 3073 3057 3018 2958 3015 3028 3060 3074 3095 3116 3089 3032
				2991 3014 3054 3123 3186 3180 3157 3144 3091 2982 3039 3061 3084 3102 3117 3145 3116 3071
				3005 3018 3059 3129 3199 3193 3169 3155 3099 3042 3105 3124 3150 3165 3183 3207 3185 3147
				3040 3054 3094 3166 3235 3227 3201 3187 3130 2997 3061 3084 3105 3127 3140 3165 3151 3116
				3032 3042 3081 3152 3225 3232 3207 3190 3127 3075 3150 3171 3196 3217 3231 3255 3248 3211
				3103 3131 3168 3178 3178 3164 3168 3148 3115 3236 3257 3285 3281 3276 3192 3106 3042 2997
				3155 3179 3220 3232 3225 3220 3210 3197 3161 3267 3292 3311 3319 3323 3246 3155 3091 3049
				3171 3196 3239 3259 3249 3245 3224 3215 3173 3274 3305 3322 3341 3346 3271 3176 3113 3068
				3211 3238 3290 3304 3298 3295 3278 3259 3218 3326 3360 3388 3403 3414 3334 3242 3180 3133
				3260 3281 3334 3348 3337 3327 3311 3287 3255 3337 3365 3390 3411 3423 3360 3267 3204 3161
				3297 3319 3376 3395 3385 3375 3346 3325 3294 3396 3424 3446 3480 3490 3427 3332 3267 3224
				3288 3306 3393 3402 3397 3381 3360 3340 3319 3397 3421 3445 3474 3491 3430 3344 3262 3213
				3339 3367 3442 3460 3442 3431 3406 3386 3364 3441 3467 3488 3519 3535 3490 3404 3323 3270
				3372 3403 3477 3491 3477 3456 3439 3423 3393 3467 3495 3519 3536 3567 3519 3444 3362 3309
				3431 3465 3536 3563 3539 3529 3501 3487 3453 3505 3536 3563 3588 3610 3581 3502 3421 3367
				3441 3467 3540 3556 3544 3529 3505 3486 3458 3521 3549 3577 3599 3623 3591 3526 3444 3392
				3480 3512 3575 3591 3579 3565 3539 3522 3487 3570 3600 3628 3655 3679 3652 3591 3515 3460
				3542 3563 3635 3637 3634 3621 3600 3574 3542 3585 3627 3649 3682 3696 3675 3617 3553 3491
				3591 3613 3682 3694 3686 3669 3648 3621 3588 3621 3661 3687 3717 3738 3729 3672 3605 3544
				3609 3620 3684 3705 3694 3682 3662 3635 3599 3617 3661 3682 3714 3729 3729 3666 3607 3556
				3665 3673 3738 3763 3746 3731 3707 3680 3644 3676 3721 3747 3778 3796 3806 3752 3687 3644
				3711 3724 3773 3830 3827 3815 3791 3771 3728 3683 3729 3752 3784 3802 3826 3798 3752 3708
				3717 3726 3770 3819 3823 3809 3787 3766 3724 3739 3789 3813 3843 3861 3883 3872 3820 3780
				3789 3791 3837 3882 3889 3876 3857 3834 3794 3719 3767 3794 3823 3840 3862 3859 3809 3777
				3764 3761 3805 3844 3855 3841 3824 3802 3761 3788 3834 3861 3886 3904 3925 3927 3880 3854
				3644 3855 3886 3927 3936 3927 3928 3910 3872 3801 3844 3868 3871 3890 3907 3911 3875 3628
				3641 3855 3890 3918 3932 3922 3924 3901 3868 3873 3917 3941 3945 3966 3983 3998 3966 3705
				3673 3894 3924 3955 3970 3962 3959 3943 3904 3827 3873 3893 3903 3920 3938 3955 3929 3668
				3654 3873 3903 3927 3942 3934 3932 3918 3880 3892 3939 3957 3966 3983 4002 4026 4002 3736
				3721 3948 3970 3988 4002 3992 3994 3980 3946 3861 3904 3922 3931 3949 3966 3991 3978 3711
				3775 3845 3957 3973 3987 3978 3980 3967 3927 3922 3970 3985 3997 4013 4036 4062 3956 3847
				>;

			PS_Config_Lmt_Open_Rawdata_N = <
				1365 1373 1374 1384 1396 1379 1368 1402 (-65535) (-65535) 1354 1323 1338 1357 1377 1402 1411 1387
				1251 1258 1277 1303 1327 1324 1317 1310 1293 1267 1292 1297 1311 1317 1326 1335 1324 1299
				1282 1291 1309 1338 1365 1363 1353 1347 1324 1278 1302 1312 1321 1329 1336 1348 1335 1316
				1288 1293 1311 1341 1371 1368 1358 1352 1328 1303 1330 1339 1350 1356 1364 1374 1365 1348
				1303 1309 1326 1357 1386 1383 1372 1366 1341 1284 1312 1321 1330 1340 1345 1356 1350 1335
				1299 1303 1320 1351 1382 1385 1374 1367 1340 1318 1350 1359 1369 1378 1384 1395 1392 1376
				1330 1342 1357 1362 1362 1356 1357 1349 1335 1387 1396 1408 1406 1404 1368 1331 1303 1284
				1352 1362 1380 1385 1382 1380 1375 1370 1354 1400 1411 1419 1422 1424 1391 1352 1324 1306
				1359 1369 1388 1396 1392 1390 1381 1378 1360 1403 1416 1423 1432 1434 1402 1361 1334 1315
				1376 1387 1410 1416 1413 1412 1405 1396 1379 1425 1440 1452 1458 1463 1429 1389 1363 1342
				1397 1406 1429 1435 1430 1426 1419 1408 1395 1430 1442 1453 1462 1467 1440 1400 1373 1354
				1413 1422 1447 1455 1450 1446 1434 1425 1411 1455 1467 1477 1491 1495 1468 1428 1400 1381
				1409 1417 1454 1458 1456 1449 1440 1431 1422 1456 1466 1476 1489 1496 1470 1433 1398 1377
				1431 1443 1475 1483 1475 1470 1459 1451 1441 1474 1486 1495 1508 1515 1495 1459 1424 1401
				1445 1458 1490 1496 1490 1481 1474 1467 1454 1486 1498 1508 1515 1528 1508 1476 1441 1418
				1470 1485 1515 1527 1516 1512 1500 1494 1480 1502 1515 1527 1537 1547 1534 1501 1466 1443
				1474 1486 1517 1524 1519 1512 1502 1494 1482 1509 1521 1533 1542 1552 1539 1511 1476 1453
				1491 1505 1532 1539 1534 1528 1516 1509 1494 1530 1543 1555 1566 1576 1565 1539 1506 1483
				1518 1527 1558 1558 1557 1552 1543 1531 1518 1536 1554 1564 1578 1584 1575 1550 1522 1496
				1539 1548 1578 1583 1579 1572 1563 1552 1537 1552 1569 1580 1593 1602 1598 1573 1545 1519
				1546 1551 1579 1588 1583 1578 1569 1558 1542 1550 1569 1578 1591 1598 1598 1571 1546 1524
				1570 1574 1602 1612 1605 1599 1588 1577 1561 1575 1594 1606 1619 1627 1631 1608 1580 1561
				1590 1596 1617 1641 1640 1635 1624 1616 1597 1578 1598 1608 1621 1629 1639 1627 1608 1589
				1593 1597 1615 1636 1638 1632 1623 1614 1596 1602 1624 1634 1647 1654 1664 1659 1637 1620
				1624 1624 1644 1663 1666 1661 1653 1643 1626 1594 1614 1626 1638 1645 1655 1654 1632 1618
				1613 1612 1630 1647 1652 1646 1639 1629 1612 1623 1643 1654 1665 1673 1682 1683 1663 1651
				1561 1652 1665 1683 1687 1683 1683 1675 1659 1629 1647 1657 1659 1667 1674 1676 1660 1555
				1560 1652 1667 1679 1685 1681 1681 1672 1657 1660 1678 1689 1690 1699 1707 1713 1699 1588
				1574 1669 1681 1695 1701 1698 1696 1690 1673 1640 1660 1668 1672 1680 1687 1695 1684 1572
				1566 1660 1672 1683 1689 1686 1685 1679 1663 1668 1688 1696 1699 1707 1715 1725 1715 1601
				1594 1692 1701 1709 1715 1711 1711 1705 1691 1654 1673 1681 1684 1692 1699 1710 1705 1590
				1618 1648 1696 1702 1708 1705 1705 1700 1683 1681 1701 1708 1713 1720 1729 1741 1695 1648
				>;

			PS_Config_Lmt_FW_Rawdata_P = <
				2252 2242 2247 2238 2242 2255 2226 2233 65535 65535 2258 2241 2252 2233 2217 2220 2223 2228
				2252 2231 2238 2233 2230 2234 2231 2247 2244 2247 2238 2235 2227 2249 2245 2237 2234 2252
				2261 2242 2248 2231 2227 2228 2223 2213 2224 2248 2237 2242 2242 2254 2248 2240 2210 2255
				2220 2234 2245 2251 2245 2244 2235 2244 2248 2221 2238 2228 2221 2227 2209 2240 2266 2228
				2230 2241 2242 2234 2217 2226 2223 2217 2235 2240 2233 2251 2237 2249 2241 2235 2231 2263
				2244 2251 2265 2237 2231 2226 2221 2223 2247 2245 2244 2240 2238 2254 2235 2237 2265 2217
				2249 2251 2231 2231 2241 2247 2247 2235 2248 2252 2240 2244 2245 2245 2233 2230 2220 2228
				2227 2240 2254 2248 2224 2214 2231 2242 2252 2244 2230 2228 2233 2240 2240 2238 2245 2240
				2247 2224 2224 2221 2235 2233 2226 2234 2234 2238 2235 2230 2237 2240 2221 2224 2220 2262
				2221 2258 2241 2249 2244 2234 2240 2241 2241 2242 2241 2234 2228 2234 2244 2255 2231 2235
				2244 2237 2245 2241 2248 2245 2251 2242 2244 2238 2223 2221 2224 2242 2244 2251 2238 2276
				2254 2223 2245 2233 2245 2247 2235 2237 2227 2228 2231 2231 2224 2217 2224 2247 2244 2244
				2240 2238 2237 2241 2242 2240 2230 2224 2237 2258 2238 2238 2237 2238 2244 2248 2247 2227
				2238 2226 2227 2220 2237 2226 2224 2235 2238 2238 2248 2242 2255 2244 2248 2226 2224 2247
				2249 2226 2248 2251 2244 2265 2251 2238 2234 2249 2234 2237 2235 2252 2254 2241 2252 2219
				2261 2241 2240 2249 2266 2262 2255 2244 2259 2237 2256 2259 2258 2242 2221 2244 2240 2245
				2226 2259 2254 2256 2252 2242 2254 2265 2252 2233 2234 2242 2244 2234 2234 2248 2235 2259
				2242 2212 2223 2230 2223 2227 2220 2230 2221 2233 2245 2242 2240 2240 2240 2226 2255 2235
				2227 2237 2238 2235 2230 2230 2227 2245 2231 2245 2248 2247 2254 2244 2241 2223 2244 2217
				2254 2244 2235 2238 2228 2230 2224 2234 2249 2234 2241 2242 2256 2240 2237 2240 2265 2227
				2247 2245 2245 2235 2234 2245 2244 2248 2238 2234 2234 2223 2237 2245 2237 2233 2252 2233
				2256 2244 2227 2252 2245 2249 2249 2247 2242 2249 2227 2234 2237 2233 2235 2242 2233 2251
				2224 2256 2237 2248 2227 2227 2220 2227 2223 2237 2237 2241 2230 2238 2249 2249 2223 2254
				2226 2230 2231 2242 2230 2244 2248 2245 2251 2228 2231 2234 2252 2226 2249 2248 2249 2251
				2242 2224 2244 2247 2235 2231 2224 2226 2227 2238 2255 2255 2251 2256 2238 2234 2234 2233
				2258 2238 2231 2248 2240 2254 2255 2242 2237 2231 2235 2256 2261 2237 2247 2245 2233 2240
				2248 2255 2224 2230 2217 2237 2231 2242 2231 2247 2252 2244 2245 2237 2241 2258 2230 2245
				2252 2254 2233 2223 2217 2224 2212 2226 2238 2237 2238 2237 2244 2244 2241 2248 2235 2235
				2248 2263 2221 2228 2234 2258 2237 2220 2242 2224 2237 2231 2237 2237 2233 2238 2248 2242
				2268 2263 2237 2245 2221 2216 2226 2244 2248 2241 2241 2240 2248 2247 2235 2244 2240 2242
				2262 2238 2238 2237 2241 2256 2245 2241 2247 2251 2240 2244 2244 2240 2249 2249 2227 2237
				2238 2235 2255 2268 2251 2251 2244 2251 2231 2249 2240 2235 2241 2252 2245 2248 2245 2261
				>;

			PS_Config_Lmt_FW_Rawdata_N = <
				965 961 963 959 961 966 954 957 (-65535) (-65535) 967 960 965 957 950 951 952 955
				965 956 959 957 955 957 956 963 961 963 959 958 954 964 962 958 957 965
				969 961 963 956 954 955 952 948 953 963 958 961 961 966 963 960 947 966
				951 957 962 964 962 961 958 961 963 952 959 955 952 954 946 960 971 955
				955 960 961 957 950 954 952 950 958 960 957 964 958 964 960 958 956 970
				961 964 970 958 956 954 952 952 963 962 961 960 959 966 958 958 970 950
				964 964 956 956 960 963 963 958 963 965 960 961 962 962 957 955 951 955
				954 960 966 963 953 949 956 961 965 961 955 955 957 960 960 959 962 960
				963 953 953 952 958 957 954 957 957 959 958 955 958 960 952 953 951 969
				952 967 960 964 961 957 960 960 960 961 960 957 955 957 961 966 956 958
				961 958 962 960 963 962 964 961 961 959 952 952 953 961 961 964 959 975
				966 952 962 957 962 963 958 958 954 955 956 956 953 950 953 963 961 961
				960 959 958 960 961 960 955 953 958 967 959 959 958 959 961 963 963 954
				959 954 954 951 958 954 953 958 959 959 963 961 966 961 963 954 953 963
				964 954 963 964 961 970 964 959 957 964 957 958 958 965 966 960 965 951
				969 960 960 964 971 969 966 961 968 958 967 968 967 961 952 961 960 962
				954 968 966 967 965 961 966 970 965 957 957 961 961 957 957 963 958 968
				961 948 952 955 952 954 951 955 952 957 962 961 960 960 960 954 966 958
				954 958 959 958 955 955 954 962 956 962 963 963 966 961 960 952 961 950
				966 961 958 959 955 955 953 957 964 957 960 961 967 960 958 960 970 954
				963 962 962 958 957 962 961 963 959 957 957 952 958 962 958 957 965 957
				967 961 954 965 962 964 964 963 961 964 954 957 958 957 958 961 957 964
				953 967 958 963 954 954 951 954 952 958 958 960 955 959 964 964 952 966
				954 955 956 961 955 961 963 962 964 955 956 957 965 954 964 963 964 964
				961 953 961 963 958 956 953 954 954 959 966 966 964 967 959 957 957 957
				967 959 956 963 960 966 966 961 958 956 958 967 969 958 963 962 957 960
				963 966 953 955 950 958 956 961 956 963 965 961 962 958 960 967 955 962
				965 966 957 952 950 953 948 954 959 958 959 958 961 961 960 963 958 958
				963 970 952 955 957 967 958 951 961 953 958 956 958 958 957 959 963 961
				972 970 958 962 952 949 954 961 963 960 960 960 963 963 958 961 960 961
				969 959 959 958 960 967 962 960 963 964 960 961 961 960 964 964 954 958
				959 958 966 972 964 964 961 964 956 964 960 958 960 965 962 963 962 969
				>;

			PS_Config_Lmt_FW_CC_P = <
				97 97 97 97 99 99 100 100 65535 65535 102 102 100 100 100 100 100 100
				100 99 99 99 99 99 99 99 102 106 104 104 104 103 103 104 104 106
				102 100 100 100 100 100 100 102 104 104 102 102 103 102 102 103 103 104
				102 100 99 100 100 100 100 100 103 107 104 104 104 104 104 104 106 107
				103 102 102 102 102 102 102 102 106 106 103 103 103 103 103 103 104 106
				102 100 100 100 100 100 100 102 104 109 106 106 106 106 106 106 106 109
				103 102 102 102 102 102 102 102 104 109 106 106 106 106 104 104 104 107
				107 104 104 104 104 104 104 104 107 111 109 109 109 109 107 107 107 109
				104 103 102 102 102 102 102 102 104 107 106 106 106 104 104 104 104 106
				107 106 104 104 104 104 104 104 107 111 110 110 110 110 109 109 109 110
				104 103 103 103 103 102 103 103 106 109 107 107 107 107 106 104 106 107
				107 106 106 106 106 106 106 106 109 113 110 110 110 110 110 109 109 111
				104 103 103 104 103 103 103 103 106 109 106 106 106 106 106 104 106 107
				107 106 106 106 106 106 106 106 109 113 110 110 110 110 110 109 109 111
				106 103 103 103 103 103 103 103 106 109 107 107 107 106 106 106 106 109
				107 106 106 106 106 106 106 106 109 113 110 110 110 110 110 109 110 111
				106 104 104 104 103 103 103 104 106 110 107 107 107 107 106 106 106 109
				107 106 106 106 106 106 106 106 109 114 111 111 111 111 111 110 110 113
				106 104 104 104 104 104 104 104 107 109 106 107 107 106 106 106 107 109
				109 107 107 107 107 107 107 107 110 111 109 110 110 109 110 109 110 111
				106 104 104 104 104 103 103 104 107 109 107 107 107 107 107 107 107 109
				109 107 107 107 107 106 106 107 110 113 110 110 110 110 110 110 111 113
				107 104 104 104 104 103 104 104 107 107 104 104 104 104 104 104 106 107
				104 103 103 103 103 102 102 102 104 110 107 107 109 107 109 109 109 111
				107 104 104 104 104 104 104 104 107 107 104 104 106 104 106 106 106 109
				104 103 103 103 102 102 102 102 104 110 107 107 109 107 109 109 109 111
				104 104 104 104 104 104 104 104 107 109 106 106 107 106 107 107 107 107
				103 103 103 103 103 103 103 103 106 111 109 109 109 107 109 109 109 109
				104 104 104 104 103 103 103 103 107 109 106 106 106 106 106 106 107 106
				103 103 103 103 102 102 102 103 106 111 109 109 109 109 109 109 109 109
				104 104 103 103 103 103 103 103 106 109 106 106 106 106 106 106 106 106
				103 102 102 102 102 102 102 103 106 111 109 109 109 107 107 109 109 109
				>;

			PS_Config_Lmt_FW_CC_N = <
				44 44 44 44 44 44 45 45 (-65535) (-65535) 45 45 45 45 45 45 45 45
				45 44 44 44 44 44 44 44 45 47 47 47 47 46 46 47 47 47
				45 45 45 45 45 45 45 45 47 47 45 45 46 45 45 46 46 47
				45 45 44 45 45 45 45 45 46 48 47 47 47 47 47 47 47 48
				46 45 45 45 45 45 45 45 47 47 46 46 46 46 46 46 47 47
				45 45 45 45 45 45 45 45 47 48 47 47 47 47 47 47 47 48
				46 45 45 45 45 45 45 45 47 48 47 47 47 47 47 47 47 48
				48 47 47 47 47 47 47 47 48 50 48 48 48 48 48 48 48 48
				47 46 45 45 45 45 45 45 47 48 47 47 47 47 47 47 47 47
				48 47 47 47 47 47 47 47 48 50 49 49 49 49 48 48 48 49
				47 46 46 46 46 45 46 46 47 48 48 48 48 48 47 47 47 48
				48 47 47 47 47 47 47 47 48 50 49 49 49 49 49 48 48 50
				47 46 46 47 46 46 46 46 47 48 47 47 47 47 47 47 47 48
				48 47 47 47 47 47 47 47 48 50 49 49 49 49 49 48 48 50
				47 46 46 46 46 46 46 46 47 48 48 48 48 47 47 47 47 48
				48 47 47 47 47 47 47 47 48 50 49 49 49 49 49 48 49 50
				47 47 47 47 46 46 46 47 47 49 48 48 48 48 47 47 47 48
				48 47 47 47 47 47 47 47 48 51 50 50 50 50 50 49 49 50
				47 47 47 47 47 47 47 47 48 48 47 48 48 47 47 47 48 48
				48 48 48 48 48 48 48 48 49 50 48 49 49 48 49 48 49 50
				47 47 47 47 47 46 46 47 48 48 48 48 48 48 48 48 48 48
				48 48 48 48 48 47 47 48 49 50 49 49 49 49 49 49 50 50
				48 47 47 47 47 46 47 47 48 48 47 47 47 47 47 47 47 48
				47 46 46 46 46 45 45 45 47 49 48 48 48 48 48 48 48 50
				48 47 47 47 47 47 47 47 48 48 47 47 47 47 47 47 47 48
				47 46 46 46 45 45 45 45 47 49 48 48 48 48 48 48 48 50
				47 47 47 47 47 47 47 47 48 48 47 47 48 47 48 48 48 48
				46 46 46 46 46 46 46 46 47 50 48 48 48 48 48 48 48 48
				47 47 47 47 46 46 46 46 48 48 47 47 47 47 47 47 48 47
				46 46 46 46 45 45 45 46 47 50 48 48 48 48 48 48 48 48
				47 47 46 46 46 46 46 46 47 48 47 47 47 47 47 47 47 47
				46 45 45 45 45 45 45 46 47 50 48 48 48 48 48 48 48 48
				>;

			PS_Config_Lmt_FW_Diff_P = <
				50 50 50 50 50 50 50 50 65535 65535 50 50 50 50 50 50 50 50
				50 50 50 50 50 50 50 50 50 50 50 50 50 50 50 50 50 50
				50 50 50 50 50 50 50 50 50 50 50 50 50 50 50 50 50 50
				50 50 50 50 50 50 50 50 50 50 50 50 50 50 50 50 50 50
				50 50 50 50 50 50 50 50 50 50 50 50 50 50 50 50 50 50
				50 50 50 50 50 50 50 50 50 50 50 50 50 50 50 50 50 50
				50 50 50 50 50 50 50 50 50 50 50 50 50 50 50 50 50 50
				50 50 50 50 50 50 50 50 50 50 50 50 50 50 50 50 50 50
				50 50 50 50 50 50 50 50 50 50 50 50 50 50 50 50 50 50
				50 50 50 50 50 50 50 50 50 50 50 50 50 50 50 50 50 50
				50 50 50 50 50 50 50 50 50 50 50 50 50 50 50 50 50 50
				50 50 50 50 50 50 50 50 50 50 50 50 50 50 50 50 50 50
				50 50 50 50 50 50 50 50 50 50 50 50 50 50 50 50 50 50
				50 50 50 50 50 50 50 50 50 50 50 50 50 50 50 50 50 50
				50 50 50 50 50 50 50 50 50 50 50 50 50 50 50 50 50 50
				50 50 50 50 50 50 50 50 50 50 50 50 50 50 50 50 50 50
				50 50 50 50 50 50 50 50 50 50 50 50 50 50 50 50 50 50
				50 50 50 50 50 50 50 50 50 50 50 50 50 50 50 50 50 50
				50 50 50 50 50 50 50 50 50 50 50 50 50 50 50 50 50 50
				50 50 50 50 50 50 50 50 50 50 50 50 50 50 50 50 50 50
				50 50 50 50 50 50 50 50 50 50 50 50 50 50 50 50 50 50
				50 50 50 50 50 50 50 50 50 50 50 50 50 50 50 50 50 50
				50 50 50 50 50 50 50 50 50 50 50 50 50 50 50 50 50 50
				50 50 50 50 50 50 50 50 50 50 50 50 50 50 50 50 50 50
				50 50 50 50 50 50 50 50 50 50 50 50 50 50 50 50 50 50
				50 50 50 50 50 50 50 50 50 50 50 50 50 50 50 50 50 50
				50 50 50 50 50 50 50 50 50 50 50 50 50 50 50 50 50 50
				50 50 50 50 50 50 50 50 50 50 50 50 50 50 50 50 50 50
				50 50 50 50 50 50 50 50 50 50 50 50 50 50 50 50 50 50
				50 50 50 50 50 50 50 50 50 50 50 50 50 50 50 50 50 50
				50 50 50 50 50 50 50 50 50 50 50 50 50 50 50 50 50 50
				50 50 50 50 50 50 50 50 50 50 50 50 50 50 50 50 50 50
				>;

			PS_Config_Lmt_FW_Diff_N = <
				(-50) (-50) (-50) (-50) (-50) (-50) (-50) (-50) (-65535) (-65535) (-50) (-50) (-50) (-50) (-50) (-50) (-50) (-50)
				(-50) (-50) (-50) (-50) (-50) (-50) (-50) (-50) (-50) (-50) (-50) (-50) (-50) (-50) (-50) (-50) (-50) (-50)
				(-50) (-50) (-50) (-50) (-50) (-50) (-50) (-50) (-50) (-50) (-50) (-50) (-50) (-50) (-50) (-50) (-50) (-50)
				(-50) (-50) (-50) (-50) (-50) (-50) (-50) (-50) (-50) (-50) (-50) (-50) (-50) (-50) (-50) (-50) (-50) (-50)
				(-50) (-50) (-50) (-50) (-50) (-50) (-50) (-50) (-50) (-50) (-50) (-50) (-50) (-50) (-50) (-50) (-50) (-50)
				(-50) (-50) (-50) (-50) (-50) (-50) (-50) (-50) (-50) (-50) (-50) (-50) (-50) (-50) (-50) (-50) (-50) (-50)
				(-50) (-50) (-50) (-50) (-50) (-50) (-50) (-50) (-50) (-50) (-50) (-50) (-50) (-50) (-50) (-50) (-50) (-50)
				(-50) (-50) (-50) (-50) (-50) (-50) (-50) (-50) (-50) (-50) (-50) (-50) (-50) (-50) (-50) (-50) (-50) (-50)
				(-50) (-50) (-50) (-50) (-50) (-50) (-50) (-50) (-50) (-50) (-50) (-50) (-50) (-50) (-50) (-50) (-50) (-50)
				(-50) (-50) (-50) (-50) (-50) (-50) (-50) (-50) (-50) (-50) (-50) (-50) (-50) (-50) (-50) (-50) (-50) (-50)
				(-50) (-50) (-50) (-50) (-50) (-50) (-50) (-50) (-50) (-50) (-50) (-50) (-50) (-50) (-50) (-50) (-50) (-50)
				(-50) (-50) (-50) (-50) (-50) (-50) (-50) (-50) (-50) (-50) (-50) (-50) (-50) (-50) (-50) (-50) (-50) (-50)
				(-50) (-50) (-50) (-50) (-50) (-50) (-50) (-50) (-50) (-50) (-50) (-50) (-50) (-50) (-50) (-50) (-50) (-50)
				(-50) (-50) (-50) (-50) (-50) (-50) (-50) (-50) (-50) (-50) (-50) (-50) (-50) (-50) (-50) (-50) (-50) (-50)
				(-50) (-50) (-50) (-50) (-50) (-50) (-50) (-50) (-50) (-50) (-50) (-50) (-50) (-50) (-50) (-50) (-50) (-50)
				(-50) (-50) (-50) (-50) (-50) (-50) (-50) (-50) (-50) (-50) (-50) (-50) (-50) (-50) (-50) (-50) (-50) (-50)
				(-50) (-50) (-50) (-50) (-50) (-50) (-50) (-50) (-50) (-50) (-50) (-50) (-50) (-50) (-50) (-50) (-50) (-50)
				(-50) (-50) (-50) (-50) (-50) (-50) (-50) (-50) (-50) (-50) (-50) (-50) (-50) (-50) (-50) (-50) (-50) (-50)
				(-50) (-50) (-50) (-50) (-50) (-50) (-50) (-50) (-50) (-50) (-50) (-50) (-50) (-50) (-50) (-50) (-50) (-50)
				(-50) (-50) (-50) (-50) (-50) (-50) (-50) (-50) (-50) (-50) (-50) (-50) (-50) (-50) (-50) (-50) (-50) (-50)
				(-50) (-50) (-50) (-50) (-50) (-50) (-50) (-50) (-50) (-50) (-50) (-50) (-50) (-50) (-50) (-50) (-50) (-50)
				(-50) (-50) (-50) (-50) (-50) (-50) (-50) (-50) (-50) (-50) (-50) (-50) (-50) (-50) (-50) (-50) (-50) (-50)
				(-50) (-50) (-50) (-50) (-50) (-50) (-50) (-50) (-50) (-50) (-50) (-50) (-50) (-50) (-50) (-50) (-50) (-50)
				(-50) (-50) (-50) (-50) (-50) (-50) (-50) (-50) (-50) (-50) (-50) (-50) (-50) (-50) (-50) (-50) (-50) (-50)
				(-50) (-50) (-50) (-50) (-50) (-50) (-50) (-50) (-50) (-50) (-50) (-50) (-50) (-50) (-50) (-50) (-50) (-50)
				(-50) (-50) (-50) (-50) (-50) (-50) (-50) (-50) (-50) (-50) (-50) (-50) (-50) (-50) (-50) (-50) (-50) (-50)
				(-50) (-50) (-50) (-50) (-50) (-50) (-50) (-50) (-50) (-50) (-50) (-50) (-50) (-50) (-50) (-50) (-50) (-50)
				(-50) (-50) (-50) (-50) (-50) (-50) (-50) (-50) (-50) (-50) (-50) (-50) (-50) (-50) (-50) (-50) (-50) (-50)
				(-50) (-50) (-50) (-50) (-50) (-50) (-50) (-50) (-50) (-50) (-50) (-50) (-50) (-50) (-50) (-50) (-50) (-50)
				(-50) (-50) (-50) (-50) (-50) (-50) (-50) (-50) (-50) (-50) (-50) (-50) (-50) (-50) (-50) (-50) (-50) (-50)
				(-50) (-50) (-50) (-50) (-50) (-50) (-50) (-50) (-50) (-50) (-50) (-50) (-50) (-50) (-50) (-50) (-50) (-50)
				(-50) (-50) (-50) (-50) (-50) (-50) (-50) (-50) (-50) (-50) (-50) (-50) (-50) (-50) (-50) (-50) (-50) (-50)
				>;

			PS_Config_Diff_Test_Frame = <50>;

			PS_Config_Lmt_LPWG_Rawdata_P = <
				2240 2240 2240 2240 2240 2240 2240 2240 65535 65535 2240 2240 2240 2240 2240 2240 2240 2240
				2240 2240 2240 2240 2240 2240 2240 2240 2240 2240 2240 2240 2240 2240 2240 2240 2240 2240
				2240 2240 2240 2240 2240 2240 2240 2240 2240 2240 2240 2240 2240 2240 2240 2240 2240 2240
				2240 2240 2240 2240 2240 2240 2240 2240 2240 2240 2240 2240 2240 2240 2240 2240 2240 2240
				2240 2240 2240 2240 2240 2240 2240 2240 2240 2240 2240 2240 2240 2240 2240 2240 2240 2240
				2240 2240 2240 2240 2240 2240 2240 2240 2240 2240 2240 2240 2240 2240 2240 2240 2240 2240
				2240 2240 2240 2240 2240 2240 2240 2240 2240 2240 2240 2240 2240 2240 2240 2240 2240 2240
				2240 2240 2240 2240 2240 2240 2240 2240 2240 2240 2240 2240 2240 2240 2240 2240 2240 2240
				2240 2240 2240 2240 2240 2240 2240 2240 2240 2240 2240 2240 2240 2240 2240 2240 2240 2240
				2240 2240 2240 2240 2240 2240 2240 2240 2240 2240 2240 2240 2240 2240 2240 2240 2240 2240
				2240 2240 2240 2240 2240 2240 2240 2240 2240 2240 2240 2240 2240 2240 2240 2240 2240 2240
				2240 2240 2240 2240 2240 2240 2240 2240 2240 2240 2240 2240 2240 2240 2240 2240 2240 2240
				2240 2240 2240 2240 2240 2240 2240 2240 2240 2240 2240 2240 2240 2240 2240 2240 2240 2240
				2240 2240 2240 2240 2240 2240 2240 2240 2240 2240 2240 2240 2240 2240 2240 2240 2240 2240
				2240 2240 2240 2240 2240 2240 2240 2240 2240 2240 2240 2240 2240 2240 2240 2240 2240 2240
				2240 2240 2240 2240 2240 2240 2240 2240 2240 2240 2240 2240 2240 2240 2240 2240 2240 2240
				2240 2240 2240 2240 2240 2240 2240 2240 2240 2240 2240 2240 2240 2240 2240 2240 2240 2240
				2240 2240 2240 2240 2240 2240 2240 2240 2240 2240 2240 2240 2240 2240 2240 2240 2240 2240
				2240 2240 2240 2240 2240 2240 2240 2240 2240 2240 2240 2240 2240 2240 2240 2240 2240 2240
				2240 2240 2240 2240 2240 2240 2240 2240 2240 2240 2240 2240 2240 2240 2240 2240 2240 2240
				2240 2240 2240 2240 2240 2240 2240 2240 2240 2240 2240 2240 2240 2240 2240 2240 2240 2240
				2240 2240 2240 2240 2240 2240 2240 2240 2240 2240 2240 2240 2240 2240 2240 2240 2240 2240
				2240 2240 2240 2240 2240 2240 2240 2240 2240 2240 2240 2240 2240 2240 2240 2240 2240 2240
				2240 2240 2240 2240 2240 2240 2240 2240 2240 2240 2240 2240 2240 2240 2240 2240 2240 2240
				2240 2240 2240 2240 2240 2240 2240 2240 2240 2240 2240 2240 2240 2240 2240 2240 2240 2240
				2240 2240 2240 2240 2240 2240 2240 2240 2240 2240 2240 2240 2240 2240 2240 2240 2240 2240
				2240 2240 2240 2240 2240 2240 2240 2240 2240 2240 2240 2240 2240 2240 2240 2240 2240 2240
				2240 2240 2240 2240 2240 2240 2240 2240 2240 2240 2240 2240 2240 2240 2240 2240 2240 2240
				2240 2240 2240 2240 2240 2240 2240 2240 2240 2240 2240 2240 2240 2240 2240 2240 2240 2240
				2240 2240 2240 2240 2240 2240 2240 2240 2240 2240 2240 2240 2240 2240 2240 2240 2240 2240
				2240 2240 2240 2240 2240 2240 2240 2240 2240 2240 2240 2240 2240 2240 2240 2240 2240 2240
				2240 2240 2240 2240 2240 2240 2240 2240 2240 2240 2240 2240 2240 2240 2240 2240 2240 2240
				>;

			PS_Config_Lmt_LPWG_Rawdata_N = <
				960 960 960 960 960 960 960 960 (-65535) (-65535) 960 960 960 960 960 960 960 960
				960 960 960 960 960 960 960 960 960 960 960 960 960 960 960 960 960 960
				960 960 960 960 960 960 960 960 960 960 960 960 960 960 960 960 960 960
				960 960 960 960 960 960 960 960 960 960 960 960 960 960 960 960 960 960
				960 960 960 960 960 960 960 960 960 960 960 960 960 960 960 960 960 960
				960 960 960 960 960 960 960 960 960 960 960 960 960 960 960 960 960 960
				960 960 960 960 960 960 960 960 960 960 960 960 960 960 960 960 960 960
				960 960 960 960 960 960 960 960 960 960 960 960 960 960 960 960 960 960
				960 960 960 960 960 960 960 960 960 960 960 960 960 960 960 960 960 960
				960 960 960 960 960 960 960 960 960 960 960 960 960 960 960 960 960 960
				960 960 960 960 960 960 960 960 960 960 960 960 960 960 960 960 960 960
				960 960 960 960 960 960 960 960 960 960 960 960 960 960 960 960 960 960
				960 960 960 960 960 960 960 960 960 960 960 960 960 960 960 960 960 960
				960 960 960 960 960 960 960 960 960 960 960 960 960 960 960 960 960 960
				960 960 960 960 960 960 960 960 960 960 960 960 960 960 960 960 960 960
				960 960 960 960 960 960 960 960 960 960 960 960 960 960 960 960 960 960
				960 960 960 960 960 960 960 960 960 960 960 960 960 960 960 960 960 960
				960 960 960 960 960 960 960 960 960 960 960 960 960 960 960 960 960 960
				960 960 960 960 960 960 960 960 960 960 960 960 960 960 960 960 960 960
				960 960 960 960 960 960 960 960 960 960 960 960 960 960 960 960 960 960
				960 960 960 960 960 960 960 960 960 960 960 960 960 960 960 960 960 960
				960 960 960 960 960 960 960 960 960 960 960 960 960 960 960 960 960 960
				960 960 960 960 960 960 960 960 960 960 960 960 960 960 960 960 960 960
				960 960 960 960 960 960 960 960 960 960 960 960 960 960 960 960 960 960
				960 960 960 960 960 960 960 960 960 960 960 960 960 960 960 960 960 960
				960 960 960 960 960 960 960 960 960 960 960 960 960 960 960 960 960 960
				960 960 960 960 960 960 960 960 960 960 960 960 960 960 960 960 960 960
				960 960 960 960 960 960 960 960 960 960 960 960 960 960 960 960 960 960
				960 960 960 960 960 960 960 960 960 960 960 960 960 960 960 960 960 960
				960 960 960 960 960 960 960 960 960 960 960 960 960 960 960 960 960 960
				960 960 960 960 960 960 960 960 960 960 960 960 960 960 960 960 960 960
				960 960 960 960 960 960 960 960 960 960 960 960 960 960 960 960 960 960
				>;

			PS_Config_Lmt_LPWG_Diff_P = <
				60 60 60 60 60 60 60 60 65535 65535 60 60 60 60 60 60 60 60
				60 60 60 60 60 60 60 60 60 60 60 60 60 60 60 60 60 60
				60 60 60 60 60 60 60 60 60 60 60 60 60 60 60 60 60 60
				60 60 60 60 60 60 60 60 60 60 60 60 60 60 60 60 60 60
				60 60 60 60 60 60 60 60 60 60 60 60 60 60 60 60 60 60
				60 60 60 60 60 60 60 60 60 60 60 60 60 60 60 60 60 60
				60 60 60 60 60 60 60 60 60 60 60 60 60 60 60 60 60 60
				60 60 60 60 60 60 60 60 60 60 60 60 60 60 60 60 60 60
				60 60 60 60 60 60 60 60 60 60 60 60 60 60 60 60 60 60
				60 60 60 60 60 60 60 60 60 60 60 60 60 60 60 60 60 60
				60 60 60 60 60 60 60 60 60 60 60 60 60 60 60 60 60 60
				60 60 60 60 60 60 60 60 60 60 60 60 60 60 60 60 60 60
				60 60 60 60 60 60 60 60 60 60 60 60 60 60 60 60 60 60
				60 60 60 60 60 60 60 60 60 60 60 60 60 60 60 60 60 60
				60 60 60 60 60 60 60 60 60 60 60 60 60 60 60 60 60 60
				60 60 60 60 60 60 60 60 60 60 60 60 60 60 60 60 60 60
				60 60 60 60 60 60 60 60 60 60 60 60 60 60 60 60 60 60
				60 60 60 60 60 60 60 60 60 60 60 60 60 60 60 60 60 60
				60 60 60 60 60 60 60 60 60 60 60 60 60 60 60 60 60 60
				60 60 60 60 60 60 60 60 60 60 60 60 60 60 60 60 60 60
				60 60 60 60 60 60 60 60 60 60 60 60 60 60 60 60 60 60
				60 60 60 60 60 60 60 60 60 60 60 60 60 60 60 60 60 60
				60 60 60 60 60 60 60 60 60 60 60 60 60 60 60 60 60 60
				60 60 60 60 60 60 60 60 60 60 60 60 60 60 60 60 60 60
				60 60 60 60 60 60 60 60 60 60 60 60 60 60 60 60 60 60
				60 60 60 60 60 60 60 60 60 60 60 60 60 60 60 60 60 60
				60 60 60 60 60 60 60 60 60 60 60 60 60 60 60 60 60 60
				60 60 60 60 60 60 60 60 60 60 60 60 60 60 60 60 60 60
				60 60 60 60 60 60 60 60 60 60 60 60 60 60 60 60 60 60
				60 60 60 60 60 60 60 60 60 60 60 60 60 60 60 60 60 60
				60 60 60 60 60 60 60 60 60 60 60 60 60 60 60 60 60 60
				60 60 60 60 60 60 60 60 60 60 60 60 60 60 60 60 60 60
				>;

			PS_Config_Lmt_LPWG_Diff_N = <
				(-60) (-60) (-60) (-60) (-60) (-60) (-60) (-60) (-65535) (-65535) (-60) (-60) (-60) (-60) (-60) (-60) (-60) (-60)
				(-60) (-60) (-60) (-60) (-60) (-60) (-60) (-60) (-60) (-60) (-60) (-60) (-60) (-60) (-60) (-60) (-60) (-60)
				(-60) (-60) (-60) (-60) (-60) (-60) (-60) (-60) (-60) (-60) (-60) (-60) (-60) (-60) (-60) (-60) (-60) (-60)
				(-60) (-60) (-60) (-60) (-60) (-60) (-60) (-60) (-60) (-60) (-60) (-60) (-60) (-60) (-60) (-60) (-60) (-60)
				(-60) (-60) (-60) (-60) (-60) (-60) (-60) (-60) (-60) (-60) (-60) (-60) (-60) (-60) (-60) (-60) (-60) (-60)
				(-60) (-60) (-60) (-60) (-60) (-60) (-60) (-60) (-60) (-60) (-60) (-60) (-60) (-60) (-60) (-60) (-60) (-60)
				(-60) (-60) (-60) (-60) (-60) (-60) (-60) (-60) (-60) (-60) (-60) (-60) (-60) (-60) (-60) (-60) (-60) (-60)
				(-60) (-60) (-60) (-60) (-60) (-60) (-60) (-60) (-60) (-60) (-60) (-60) (-60) (-60) (-60) (-60) (-60) (-60)
				(-60) (-60) (-60) (-60) (-60) (-60) (-60) (-60) (-60) (-60) (-60) (-60) (-60) (-60) (-60) (-60) (-60) (-60)
				(-60) (-60) (-60) (-60) (-60) (-60) (-60) (-60) (-60) (-60) (-60) (-60) (-60) (-60) (-60) (-60) (-60) (-60)
				(-60) (-60) (-60) (-60) (-60) (-60) (-60) (-60) (-60) (-60) (-60) (-60) (-60) (-60) (-60) (-60) (-60) (-60)
				(-60) (-60) (-60) (-60) (-60) (-60) (-60) (-60) (-60) (-60) (-60) (-60) (-60) (-60) (-60) (-60) (-60) (-60)
				(-60) (-60) (-60) (-60) (-60) (-60) (-60) (-60) (-60) (-60) (-60) (-60) (-60) (-60) (-60) (-60) (-60) (-60)
				(-60) (-60) (-60) (-60) (-60) (-60) (-60) (-60) (-60) (-60) (-60) (-60) (-60) (-60) (-60) (-60) (-60) (-60)
				(-60) (-60) (-60) (-60) (-60) (-60) (-60) (-60) (-60) (-60) (-60) (-60) (-60) (-60) (-60) (-60) (-60) (-60)
				(-60) (-60) (-60) (-60) (-60) (-60) (-60) (-60) (-60) (-60) (-60) (-60) (-60) (-60) (-60) (-60) (-60) (-60)
				(-60) (-60) (-60) (-60) (-60) (-60) (-60) (-60) (-60) (-60) (-60) (-60) (-60) (-60) (-60) (-60) (-60) (-60)
				(-60) (-60) (-60) (-60) (-60) (-60) (-60) (-60) (-60) (-60) (-60) (-60) (-60) (-60) (-60) (-60) (-60) (-60)
				(-60) (-60) (-60) (-60) (-60) (-60) (-60) (-60) (-60) (-60) (-60) (-60) (-60) (-60) (-60) (-60) (-60) (-60)
				(-60) (-60) (-60) (-60) (-60) (-60) (-60) (-60) (-60) (-60) (-60) (-60) (-60) (-60) (-60) (-60) (-60) (-60)
				(-60) (-60) (-60) (-60) (-60) (-60) (-60) (-60) (-60) (-60) (-60) (-60) (-60) (-60) (-60) (-60) (-60) (-60)
				(-60) (-60) (-60) (-60) (-60) (-60) (-60) (-60) (-60) (-60) (-60) (-60) (-60) (-60) (-60) (-60) (-60) (-60)
				(-60) (-60) (-60) (-60) (-60) (-60) (-60) (-60) (-60) (-60) (-60) (-60) (-60) (-60) (-60) (-60) (-60) (-60)
				(-60) (-60) (-60) (-60) (-60) (-60) (-60) (-60) (-60) (-60) (-60) (-60) (-60) (-60) (-60) (-60) (-60) (-60)
				(-60) (-60) (-60) (-60) (-60) (-60) (-60) (-60) (-60) (-60) (-60) (-60) (-60) (-60) (-60) (-60) (-60) (-60)
				(-60) (-60) (-60) (-60) (-60) (-60) (-60) (-60) (-60) (-60) (-60) (-60) (-60) (-60) (-60) (-60) (-60) (-60)
				(-60) (-60) (-60) (-60) (-60) (-60) (-60) (-60) (-60) (-60) (-60) (-60) (-60) (-60) (-60) (-60) (-60) (-60)
				(-60) (-60) (-60) (-60) (-60) (-60) (-60) (-60) (-60) (-60) (-60) (-60) (-60) (-60) (-60) (-60) (-60) (-60)
				(-60) (-60) (-60) (-60) (-60) (-60) (-60) (-60) (-60) (-60) (-60) (-60) (-60) (-60) (-60) (-60) (-60) (-60)
				(-60) (-60) (-60) (-60) (-60) (-60) (-60) (-60) (-60) (-60) (-60) (-60) (-60) (-60) (-60) (-60) (-60) (-60)
				(-60) (-60) (-60) (-60) (-60) (-60) (-60) (-60) (-60) (-60) (-60) (-60) (-60) (-60) (-60) (-60) (-60) (-60)
				(-60) (-60) (-60) (-60) (-60) (-60) (-60) (-60) (-60) (-60) (-60) (-60) (-60) (-60) (-60) (-60) (-60) (-60)
				>;
		}; /* novatek-mp-criteria-hlt */

		novatek-mp-criteria-b3@1 {
			#address-cells = <1>;
			#size-cells = <0>;
			compatible = "novatek-mp-criteria-b3";

			/* MP Config */
			IC_X_CFG_SIZE = <18>;
			IC_Y_CFG_SIZE = <32>;
			IC_KEY_CFG_SIZE = <4>;
			X_Channel = <18>;
			Y_Channel = <32>;
			AIN_X = <0 1 2 3 4 5 6 7 8 9 10 11 12 13 14 15 16 17>;
			AIN_Y = <0 1 2 3 4 5 6 7 8 9 10 11 12 13 14 15 16 17 18 19
								20 21 22 23 24 25 26 27 28 29 30 31>;
			AIN_KEY = <0 1 2 0xFF>;

			/* MP Criteria */
			PS_Config_Lmt_Short_Rawdata_P = <
				14008 14008 14008 14008 14008 14008 14008 14008 14008 14008 14008 14008 14008 14008 14008 14008 14008 14008
				14008 14008 14008 14008 14008 14008 14008 14008 14008 14008 14008 14008 14008 14008 14008 14008 14008 14008
				14008 14008 14008 14008 14008 14008 14008 14008 14008 14008 14008 14008 14008 14008 14008 14008 14008 14008
				14008 14008 14008 14008 14008 14008 14008 14008 14008 14008 14008 14008 14008 14008 14008 14008 14008 14008
				14008 14008 14008 14008 14008 14008 14008 14008 14008 14008 14008 14008 14008 14008 14008 14008 14008 14008
				14008 14008 14008 14008 14008 14008 14008 14008 14008 14008 14008 14008 14008 14008 14008 14008 14008 14008
				14008 14008 14008 14008 14008 14008 14008 14008 14008 14008 14008 14008 14008 14008 14008 14008 14008 14008
				14008 14008 14008 14008 14008 14008 14008 14008 14008 14008 14008 14008 14008 14008 14008 14008 14008 14008
				14008 14008 14008 14008 14008 14008 14008 14008 14008 14008 14008 14008 14008 14008 14008 14008 14008 14008
				14008 14008 14008 14008 14008 14008 14008 14008 14008 14008 14008 14008 14008 14008 14008 14008 14008 14008
				14008 14008 14008 14008 14008 14008 14008 14008 14008 14008 14008 14008 14008 14008 14008 14008 14008 14008
				14008 14008 14008 14008 14008 14008 14008 14008 14008 14008 14008 14008 14008 14008 14008 14008 14008 14008
				14008 14008 14008 14008 14008 14008 14008 14008 14008 14008 14008 14008 14008 14008 14008 14008 14008 14008
				14008 14008 14008 14008 14008 14008 14008 14008 14008 14008 14008 14008 14008 14008 14008 14008 14008 14008
				14008 14008 14008 14008 14008 14008 14008 14008 14008 14008 14008 14008 14008 14008 14008 14008 14008 14008
				14008 14008 14008 14008 14008 14008 14008 14008 14008 14008 14008 14008 14008 14008 14008 14008 14008 14008
				14008 14008 14008 14008 14008 14008 14008 14008 14008 14008 14008 14008 14008 14008 14008 14008 14008 14008
				14008 14008 14008 14008 14008 14008 14008 14008 14008 14008 14008 14008 14008 14008 14008 14008 14008 14008
				14008 14008 14008 14008 14008 14008 14008 14008 14008 14008 14008 14008 14008 14008 14008 14008 14008 14008
				14008 14008 14008 14008 14008 14008 14008 14008 14008 14008 14008 14008 14008 14008 14008 14008 14008 14008
				14008 14008 14008 14008 14008 14008 14008 14008 14008 14008 14008 14008 14008 14008 14008 14008 14008 14008
				14008 14008 14008 14008 14008 14008 14008 14008 14008 14008 14008 14008 14008 14008 14008 14008 14008 14008
				14008 14008 14008 14008 14008 14008 14008 14008 14008 14008 14008 14008 14008 14008 14008 14008 14008 14008
				14008 14008 14008 14008 14008 14008 14008 14008 14008 14008 14008 14008 14008 14008 14008 14008 14008 14008
				14008 14008 14008 14008 14008 14008 14008 14008 14008 14008 14008 14008 14008 14008 14008 14008 14008 14008
				14008 14008 14008 14008 14008 14008 14008 14008 14008 14008 14008 14008 14008 14008 14008 14008 14008 14008
				14008 14008 14008 14008 14008 14008 14008 14008 14008 14008 14008 14008 14008 14008 14008 14008 14008 14008
				14008 14008 14008 14008 14008 14008 14008 14008 14008 14008 14008 14008 14008 14008 14008 14008 14008 14008
				14008 14008 14008 14008 14008 14008 14008 14008 14008 14008 14008 14008 14008 14008 14008 14008 14008 14008
				14008 14008 14008 14008 14008 14008 14008 14008 14008 14008 14008 14008 14008 14008 14008 14008 14008 14008
				14008 14008 14008 14008 14008 14008 14008 14008 14008 14008 14008 14008 14008 14008 14008 14008 14008 14008
				14008 14008 14008 14008 14008 14008 14008 14008 14008 14008 14008 14008 14008 14008 14008 14008 14008 14008
				>;

			PS_Config_Lmt_Short_Rawdata_N = <
				11376 11376 11376 11376 11376 11376 11376 11376 11376 11376 11376 11376 11376 11376 11376 11376 11376 11376
				11376 11376 11376 11376 11376 11376 11376 11376 11376 11376 11376 11376 11376 11376 11376 11376 11376 11376
				11376 11376 11376 11376 11376 11376 11376 11376 11376 11376 11376 11376 11376 11376 11376 11376 11376 11376
				11376 11376 11376 11376 11376 11376 11376 11376 11376 11376 11376 11376 11376 11376 11376 11376 11376 11376
				11376 11376 11376 11376 11376 11376 11376 11376 11376 11376 11376 11376 11376 11376 11376 11376 11376 11376
				11376 11376 11376 11376 11376 11376 11376 11376 11376 11376 11376 11376 11376 11376 11376 11376 11376 11376
				11376 11376 11376 11376 11376 11376 11376 11376 11376 11376 11376 11376 11376 11376 11376 11376 11376 11376
				11376 11376 11376 11376 11376 11376 11376 11376 11376 11376 11376 11376 11376 11376 11376 11376 11376 11376
				11376 11376 11376 11376 11376 11376 11376 11376 11376 11376 11376 11376 11376 11376 11376 11376 11376 11376
				11376 11376 11376 11376 11376 11376 11376 11376 11376 11376 11376 11376 11376 11376 11376 11376 11376 11376
				11376 11376 11376 11376 11376 11376 11376 11376 11376 11376 11376 11376 11376 11376 11376 11376 11376 11376
				11376 11376 11376 11376 11376 11376 11376 11376 11376 11376 11376 11376 11376 11376 11376 11376 11376 11376
				11376 11376 11376 11376 11376 11376 11376 11376 11376 11376 11376 11376 11376 11376 11376 11376 11376 11376
				11376 11376 11376 11376 11376 11376 11376 11376 11376 11376 11376 11376 11376 11376 11376 11376 11376 11376
				11376 11376 11376 11376 11376 11376 11376 11376 11376 11376 11376 11376 11376 11376 11376 11376 11376 11376
				11376 11376 11376 11376 11376 11376 11376 11376 11376 11376 11376 11376 11376 11376 11376 11376 11376 11376
				11376 11376 11376 11376 11376 11376 11376 11376 11376 11376 11376 11376 11376 11376 11376 11376 11376 11376
				11376 11376 11376 11376 11376 11376 11376 11376 11376 11376 11376 11376 11376 11376 11376 11376 11376 11376
				11376 11376 11376 11376 11376 11376 11376 11376 11376 11376 11376 11376 11376 11376 11376 11376 11376 11376
				11376 11376 11376 11376 11376 11376 11376 11376 11376 11376 11376 11376 11376 11376 11376 11376 11376 11376
				11376 11376 11376 11376 11376 11376 11376 11376 11376 11376 11376 11376 11376 11376 11376 11376 11376 11376
				11376 11376 11376 11376 11376 11376 11376 11376 11376 11376 11376 11376 11376 11376 11376 11376 11376 11376
				11376 11376 11376 11376 11376 11376 11376 11376 11376 11376 11376 11376 11376 11376 11376 11376 11376 11376
				11376 11376 11376 11376 11376 11376 11376 11376 11376 11376 11376 11376 11376 11376 11376 11376 11376 11376
				11376 11376 11376 11376 11376 11376 11376 11376 11376 11376 11376 11376 11376 11376 11376 11376 11376 11376
				11376 11376 11376 11376 11376 11376 11376 11376 11376 11376 11376 11376 11376 11376 11376 11376 11376 11376
				11376 11376 11376 11376 11376 11376 11376 11376 11376 11376 11376 11376 11376 11376 11376 11376 11376 11376
				11376 11376 11376 11376 11376 11376 11376 11376 11376 11376 11376 11376 11376 11376 11376 11376 11376 11376
				11376 11376 11376 11376 11376 11376 11376 11376 11376 11376 11376 11376 11376 11376 11376 11376 11376 11376
				11376 11376 11376 11376 11376 11376 11376 11376 11376 11376 11376 11376 11376 11376 11376 11376 11376 11376
				11376 11376 11376 11376 11376 11376 11376 11376 11376 11376 11376 11376 11376 11376 11376 11376 11376 11376
				11376 11376 11376 11376 11376 11376 11376 11376 11376 11376 11376 11376 11376 11376 11376 11376 11376 11376
				>;

			PS_Config_Lmt_Open_Rawdata_P = <
				 3140 3158 3161 3180 3206 3165 3138 3218 65535 65535 3117 3043 3084 3126 3176 3234 3257 3203
				 2865 2881 2923 2979 3035 3025 3007 2990 2952 2919 2973 2986 3019 3032 3054 3073 3050 2994
				 2944 2966 3003 3068 3131 3126 3098 3085 3032 2933 2982 3008 3031 3049 3064 3094 3066 3028
				 2955 2966 3004 3071 3138 3134 3106 3094 3038 2982 3036 3061 3087 3103 3122 3148 3127 3094
				 2989 3005 3039 3112 3180 3172 3144 3131 3071 2969 3026 3052 3074 3096 3109 3134 3120 3089
				 2973 2983 3019 3091 3162 3171 3143 3130 3068 3040 3105 3130 3155 3179 3192 3215 3210 3175
				 3060 3082 3119 3127 3126 3112 3116 3096 3071 3206 3227 3259 3250 3248 3162 3078 3015 2979
				 3110 3130 3169 3180 3173 3168 3159 3145 3120 3227 3250 3273 3280 3285 3206 3116 3052 3014
				 3108 3130 3171 3189 3178 3173 3151 3144 3110 3231 3259 3276 3295 3301 3227 3130 3071 3029
				 3147 3172 3218 3234 3227 3225 3206 3189 3152 3294 3325 3353 3369 3379 3301 3206 3145 3102
				 3197 3220 3270 3285 3274 3266 3248 3227 3200 3299 3329 3354 3378 3388 3326 3234 3172 3131
				 3243 3266 3320 3339 3329 3319 3288 3271 3245 3358 3389 3414 3449 3458 3396 3298 3235 3192
				 3245 3262 3347 3355 3354 3336 3313 3292 3277 3367 3388 3414 3444 3460 3399 3315 3232 3187
				 3278 3306 3385 3403 3388 3375 3351 3332 3315 3414 3437 3462 3491 3507 3460 3375 3292 3242
				 3323 3355 3427 3442 3428 3410 3390 3378 3353 3435 3460 3488 3505 3536 3488 3414 3332 3283
				 3371 3407 3477 3507 3480 3474 3444 3432 3402 3483 3511 3540 3567 3588 3556 3477 3396 3346
				 3399 3431 3502 3519 3509 3495 3469 3453 3424 3490 3519 3550 3574 3596 3563 3497 3411 3361
				 3448 3481 3547 3565 3556 3543 3515 3501 3467 3553 3584 3614 3638 3661 3630 3568 3490 3437
				 3497 3521 3593 3596 3598 3585 3564 3537 3508 3558 3603 3624 3661 3673 3654 3589 3525 3459
				 3537 3564 3634 3648 3644 3624 3605 3579 3547 3605 3652 3676 3710 3729 3719 3656 3589 3525
				 3568 3584 3654 3673 3663 3649 3631 3605 3571 3607 3654 3677 3712 3726 3728 3662 3598 3542
				 3610 3621 3691 3715 3703 3690 3670 3645 3612 3661 3710 3733 3767 3784 3792 3732 3662 3613
				 3669 3691 3740 3805 3803 3791 3766 3749 3704 3672 3726 3747 3785 3799 3826 3794 3745 3696
				 3679 3696 3743 3801 3805 3791 3766 3747 3703 3735 3789 3812 3845 3859 3885 3866 3812 3764
				 3745 3752 3803 3852 3866 3854 3834 3810 3768 3721 3770 3796 3826 3841 3864 3859 3803 3767
				 3750 3750 3795 3840 3855 3841 3824 3802 3761 3788 3838 3868 3894 3913 3935 3938 3885 3851
				 3607 3812 3851 3897 3911 3903 3908 3890 3852 3815 3861 3885 3886 3907 3924 3925 3885 3640
				 3612 3817 3859 3892 3910 3900 3904 3883 3847 3871 3917 3942 3946 3967 3985 4005 3964 3707
				 3661 3879 3911 3949 3969 3963 3960 3948 3904 3836 3887 3906 3917 3934 3955 3971 3942 3677
				 3638 3855 3889 3920 3942 3936 3935 3921 3880 3911 3964 3983 3994 4011 4033 4060 4030 3759
				 3708 3934 3964 3988 4011 4001 4002 3987 3949 3897 3950 3969 3977 3995 4015 4046 4023 3746
				 3773 3851 3970 3987 4012 4004 4006 3994 3949 3955 4012 4026 4037 4053 4076 4107 3999 3879
				>;

			PS_Config_Lmt_Open_Rawdata_N = <
				 1345 1353 1354 1363 1374 1356 1345 1379 (-65535) (-65535) 1336 1304 1321 1339 1361 1386 1396 1372
				 1228 1234 1252 1276 1300 1296 1288 1281 1265 1251 1274 1279 1294 1299 1309 1317 1307 1283
				 1261 1271 1287 1315 1342 1339 1327 1322 1299 1257 1278 1289 1299 1306 1313 1326 1314 1297
				 1266 1271 1287 1316 1345 1343 1331 1326 1302 1278 1301 1312 1323 1330 1338 1349 1340 1326
				 1281 1288 1302 1333 1363 1359 1347 1342 1316 1272 1297 1308 1317 1327 1332 1343 1337 1324
				 1274 1278 1294 1324 1355 1359 1347 1341 1315 1303 1330 1341 1352 1362 1368 1378 1375 1360
				 1311 1321 1336 1340 1339 1333 1335 1327 1316 1374 1383 1396 1393 1392 1355 1319 1292 1276
				 1333 1341 1358 1363 1360 1357 1354 1348 1337 1383 1393 1402 1405 1408 1374 1335 1308 1291
				 1332 1341 1359 1366 1362 1360 1350 1347 1333 1384 1396 1404 1412 1414 1383 1341 1316 1298
				 1348 1359 1379 1386 1383 1382 1374 1366 1351 1411 1425 1437 1444 1448 1414 1374 1348 1329
				 1370 1380 1401 1408 1403 1399 1392 1383 1371 1414 1426 1437 1447 1452 1425 1386 1359 1342
				 1390 1399 1423 1431 1426 1422 1409 1402 1390 1439 1452 1463 1478 1482 1455 1413 1386 1368
				 1390 1398 1434 1438 1437 1429 1420 1411 1404 1443 1452 1463 1476 1483 1456 1420 1385 1366
				 1405 1417 1450 1458 1452 1446 1436 1428 1420 1463 1473 1483 1496 1503 1483 1446 1411 1389
				 1424 1438 1468 1475 1469 1461 1453 1447 1437 1472 1483 1495 1502 1515 1495 1463 1428 1407
				 1444 1460 1490 1503 1491 1489 1476 1471 1458 1492 1504 1517 1528 1537 1524 1490 1455 1434
				 1456 1470 1501 1508 1504 1498 1486 1480 1467 1495 1508 1521 1531 1541 1527 1498 1462 1440
				 1477 1492 1520 1528 1524 1518 1506 1500 1486 1522 1536 1549 1559 1569 1555 1529 1495 1473
				 1498 1509 1540 1541 1542 1536 1527 1516 1503 1525 1544 1553 1569 1574 1566 1538 1510 1482
				 1516 1527 1557 1563 1561 1553 1545 1534 1520 1545 1565 1575 1590 1598 1594 1567 1538 1510
				 1529 1536 1566 1574 1570 1564 1556 1545 1530 1546 1566 1576 1591 1597 1597 1569 1542 1518
				 1547 1552 1582 1592 1587 1581 1573 1562 1548 1569 1590 1600 1614 1621 1625 1599 1569 1548
				 1572 1582 1603 1630 1630 1624 1614 1606 1587 1573 1597 1606 1622 1628 1639 1626 1605 1584
				 1576 1584 1604 1629 1630 1624 1614 1606 1587 1600 1624 1633 1648 1654 1665 1657 1633 1613
				 1605 1608 1630 1651 1657 1651 1643 1633 1615 1594 1615 1627 1639 1646 1656 1654 1630 1614
				 1607 1607 1626 1645 1652 1646 1639 1629 1612 1623 1645 1657 1669 1677 1686 1687 1665 1650
				 1546 1633 1650 1670 1676 1672 1675 1667 1651 1635 1654 1665 1665 1674 1681 1682 1665 1560
				 1548 1636 1654 1668 1675 1671 1673 1664 1648 1659 1678 1689 1691 1700 1708 1716 1699 1588
				 1569 1662 1676 1692 1701 1698 1697 1692 1673 1644 1666 1674 1678 1686 1695 1702 1689 1576
				 1559 1652 1666 1680 1689 1687 1686 1680 1663 1676 1699 1707 1711 1719 1728 1740 1727 1611
				 1589 1686 1699 1709 1719 1714 1715 1708 1692 1670 1693 1701 1704 1712 1720 1734 1724 1605
				 1617 1650 1701 1708 1719 1716 1717 1711 1692 1695 1719 1725 1730 1737 1747 1760 1714 1662
				>;

			PS_Config_Lmt_FW_Rawdata_P = <
				2235 2252 2241 2234 2237 2224 2248 2244 65535 65535 2238 2240 2234 2241 2256 2245 2247 2244
				2259 2245 2245 2234 2234 2234 2237 2252 2249 2256 2231 2231 2235 2233 2230 2242 2244 2238
				2241 2247 2231 2252 2242 2244 2252 2240 2233 2233 2240 2247 2259 2249 2255 2254 2230 2251
				2240 2248 2251 2252 2244 2248 2251 2234 2238 2248 2234 2241 2245 2237 2244 2234 2238 2228
				2251 2237 2231 2226 2226 2233 2233 2238 2254 2244 2242 2244 2247 2234 2235 2221 2244 2234
				2258 2247 2247 2256 2248 2245 2248 2231 2241 2235 2230 2231 2237 2237 2234 2245 2241 2242
				2228 2258 2230 2234 2219 2217 2217 2242 2226 2230 2231 2227 2226 2254 2237 2234 2240 2223
				2233 2234 2228 2233 2240 2247 2240 2241 2235 2247 2251 2256 2249 2247 2226 2219 2242 2228
				2244 2252 2240 2244 2244 2254 2258 2255 2251 2248 2234 2240 2233 2237 2241 2242 2241 2233
				2230 2248 2226 2230 2231 2233 2234 2231 2233 2231 2241 2252 2238 2238 2237 2249 2254 2244
				2233 2241 2224 2228 2242 2231 2252 2230 2241 2241 2249 2244 2244 2233 2237 2235 2258 2226
				2235 2249 2234 2242 2242 2240 2241 2245 2252 2235 2248 2248 2244 2237 2233 2231 2248 2235
				2238 2245 2234 2251 2240 2251 2244 2231 2241 2254 2238 2241 2241 2238 2233 2245 2235 2231
				2249 2235 2247 2251 2259 2251 2259 2233 2249 2241 2242 2228 2231 2254 2254 2233 2261 2242
				2233 2242 2233 2231 2228 2233 2226 2235 2234 2224 2259 2262 2249 2237 2249 2235 2248 2251
				2238 2255 2263 2263 2249 2245 2247 2265 2258 2226 2228 2233 2223 2235 2248 2241 2238 2254
				2237 2227 2244 2242 2238 2247 2247 2230 2224 2238 2237 2235 2240 2235 2237 2240 2247 2237
				2224 2242 2248 2240 2233 2231 2226 2234 2244 2258 2245 2252 2234 2252 2241 2245 2234 2251
				2242 2244 2233 2245 2237 2245 2244 2241 2231 2254 2242 2241 2249 2245 2256 2230 2245 2234
				2245 2230 2231 2240 2245 2235 2249 2241 2245 2247 2240 2238 2242 2248 2228 2237 2244 2240
				2227 2237 2234 2241 2219 2230 2230 2216 2233 2244 2234 2223 2224 2237 2233 2226 2245 2237
				2235 2242 2238 2248 2230 2235 2228 2231 2235 2244 2234 2249 2235 2255 2238 2248 2221 2237
				2256 2219 2228 2228 2231 2251 2248 2244 2240 2241 2263 2270 2265 2262 2248 2251 2233 2255
				2234 2240 2237 2235 2231 2247 2248 2242 2231 2262 2247 2247 2242 2266 2244 2242 2227 2223
				2268 2230 2258 2263 2252 2241 2241 2247 2249 2237 2241 2228 2233 2237 2221 2227 2248 2234
				2252 2234 2247 2245 2244 2231 2234 2244 2233 2247 2241 2241 2240 2245 2244 2244 2242 2245
				2224 2238 2228 2231 2233 2231 2238 2238 2242 2251 2249 2249 2244 2249 2245 2234 2227 2234
				2247 2235 2241 2251 2226 2219 2226 2237 2248 2231 2252 2259 2255 2238 2251 2258 2241 2255
				2237 2234 2227 2224 2231 2247 2238 2224 2224 2245 2247 2235 2245 2244 2245 2238 2240 2241
				2238 2244 2238 2241 2226 2227 2228 2244 2254 2245 2245 2237 2235 2242 2230 2231 2247 2244
				2241 2238 2238 2242 2220 2220 2230 2251 2251 2242 2224 2231 2240 2234 2219 2234 2249 2248
				2240 2233 2234 2238 2240 2242 2235 2237 2251 2235 2252 2258 2261 2231 2230 2228 2245 2247
				>;

			PS_Config_Lmt_FW_Rawdata_N = <
				958 965 960 957 958 953 963 961 (-65535) (-65535) 959 960 957 960 967 962 963 961
				968 962 962 957 957 957 958 965 964 967 956 956 958 957 955 961 961 959
				960 963 956 965 961 961 965 960 957 957 960 963 968 964 966 966 955 964
				960 963 964 965 961 963 964 957 959 963 957 960 962 958 961 957 959 955
				964 958 956 954 954 957 957 959 966 961 961 961 963 957 958 952 961 957
				967 963 963 967 963 962 963 956 960 958 955 956 958 958 957 962 960 961
				955 967 955 957 951 950 950 961 954 955 956 954 954 966 958 957 960 952
				957 957 955 957 960 963 960 960 958 963 964 967 964 963 954 951 961 955
				961 965 960 961 961 966 967 966 964 963 957 960 957 958 960 961 960 957
				955 963 954 955 956 957 957 956 957 956 960 965 959 959 958 964 966 961
				957 960 953 955 961 956 965 955 960 960 964 961 961 957 958 958 967 954
				958 964 957 961 961 960 960 962 965 958 963 963 961 958 957 956 963 958
				959 962 957 964 960 964 961 956 960 966 959 960 960 959 957 962 958 956
				964 958 963 964 968 964 968 957 964 960 961 955 956 966 966 957 969 961
				957 961 957 956 955 957 954 958 957 953 968 969 964 958 964 958 963 964
				959 966 970 970 964 962 963 970 967 954 955 957 952 958 963 960 959 966
				958 954 961 961 959 963 963 955 953 959 958 958 960 958 958 960 963 958
				953 961 963 960 957 956 954 957 961 967 962 965 957 965 960 962 957 964
				961 961 957 962 958 962 961 960 956 966 961 960 964 962 967 955 962 957
				962 955 956 960 962 958 964 960 962 963 960 959 961 963 955 958 961 960
				954 958 957 960 951 955 955 949 957 961 957 952 953 958 957 954 962 958
				958 961 959 963 955 958 955 956 958 961 957 964 958 966 959 963 952 958
				967 951 955 955 956 964 963 961 960 960 970 973 970 969 963 964 957 966
				957 960 958 958 956 963 963 961 956 969 963 963 961 971 961 961 954 952
				972 955 967 970 965 960 960 963 964 958 960 955 957 958 952 954 963 957
				965 957 963 962 961 956 957 961 957 963 960 960 960 962 961 961 961 962
				953 959 955 956 957 956 959 959 961 964 964 964 961 964 962 957 954 957
				963 958 960 964 954 951 954 958 963 956 965 968 966 959 964 967 960 966
				958 957 954 953 956 963 959 953 953 962 963 958 962 961 962 959 960 960
				959 961 959 960 954 954 955 961 966 962 962 958 958 961 955 956 963 961
				960 959 959 961 951 951 955 964 964 961 953 956 960 957 951 957 964 963
				960 957 957 959 960 961 958 958 964 958 965 967 969 956 955 955 962 963
				>;

			PS_Config_Lmt_FW_CC_P = <
				100 99 99 99 99 100 100 100 65535 65535 100 102 100 100 99 99 99 100
				102 99 99 99 100 99 99 99 102 107 104 104 104 104 104 104 106 107
				103 102 102 102 102 102 102 102 104 104 103 103 103 103 103 103 104 106
				102 100 100 100 100 100 100 100 103 107 106 106 106 104 106 106 107 109
				103 102 102 102 102 102 102 102 104 106 103 103 103 103 103 104 104 107
				102 100 99 100 100 100 100 100 104 109 106 106 106 106 106 107 107 110
				104 103 102 102 102 102 102 102 104 109 106 106 106 106 106 104 106 107
				107 106 104 104 104 104 104 104 107 113 110 110 110 110 109 109 109 111
				106 104 103 103 103 103 103 103 106 109 106 106 106 106 106 104 106 107
				109 106 106 106 106 104 106 106 109 113 110 110 110 110 109 109 109 111
				106 103 103 103 102 102 102 103 106 109 106 107 106 106 106 106 106 109
				109 107 106 106 106 106 106 106 109 113 110 110 110 110 110 110 110 111
				106 104 104 104 103 103 103 104 107 110 107 107 107 107 107 107 107 109
				109 106 106 106 106 106 106 106 109 113 111 111 111 110 110 110 110 113
				106 103 103 103 103 103 103 103 106 110 107 107 107 107 107 107 107 109
				109 106 106 106 106 106 106 106 109 113 110 110 110 110 110 110 110 113
				106 104 104 104 104 104 104 104 107 110 109 109 109 107 107 107 107 110
				109 107 106 106 106 106 106 106 109 113 110 110 110 110 110 110 110 113
				106 104 104 104 104 103 103 104 107 110 109 109 109 107 107 107 109 110
				109 107 106 106 106 106 106 106 109 113 111 111 111 110 111 110 111 113
				107 104 104 104 104 104 104 104 107 110 109 109 109 109 109 109 109 110
				110 109 107 107 107 107 107 107 110 114 111 111 111 111 111 111 111 114
				107 106 104 104 104 104 104 104 107 109 106 107 107 106 107 107 107 110
				106 104 103 103 103 103 103 103 106 111 109 109 109 109 109 109 110 111
				107 106 104 104 104 104 104 104 107 110 107 107 109 107 109 109 109 111
				106 104 103 103 103 103 103 103 106 111 110 110 110 110 110 110 110 113
				106 106 104 104 104 104 104 104 107 110 107 107 107 107 107 107 109 109
				104 104 104 104 103 103 103 104 107 113 110 110 110 110 110 110 110 110
				106 106 106 106 104 104 104 106 109 109 107 107 107 106 107 107 107 107
				104 104 103 103 103 103 103 103 107 111 109 109 109 109 109 109 110 110
				106 106 104 104 104 104 104 104 109 109 106 106 106 106 106 106 107 107
				104 103 103 103 103 103 103 103 107 113 109 109 109 109 109 109 109 110
				>;

			PS_Config_Lmt_FW_CC_N = <
				45 44 44 44 44 45 45 45 (-65535) (-65535) 45 45 45 45 44 44 44 45
				45 44 44 44 45 44 44 44 45 48 47 47 47 47 47 47 47 48
				46 45 45 45 45 45 45 45 47 47 46 46 46 46 46 46 47 47
				45 45 45 45 45 45 45 45 46 48 47 47 47 47 47 47 48 48
				46 45 45 45 45 45 45 45 47 47 46 46 46 46 46 47 47 48
				45 45 44 45 45 45 45 45 47 48 47 47 47 47 47 48 48 49
				47 46 45 45 45 45 45 45 47 48 47 47 47 47 47 47 47 48
				48 47 47 47 47 47 47 47 48 50 49 49 49 49 48 48 48 50
				47 47 46 46 46 46 46 46 47 48 47 47 47 47 47 47 47 48
				48 47 47 47 47 47 47 47 48 50 49 49 49 49 48 48 48 50
				47 46 46 46 45 45 45 46 47 48 47 48 47 47 47 47 47 48
				48 48 47 47 47 47 47 47 48 50 49 49 49 49 49 49 49 50
				47 47 47 47 46 46 46 47 48 49 48 48 48 48 48 48 48 48
				48 47 47 47 47 47 47 47 48 50 50 50 50 49 49 49 49 50
				47 46 46 46 46 46 46 46 47 49 48 48 48 48 48 48 48 48
				48 47 47 47 47 47 47 47 48 50 49 49 49 49 49 49 49 50
				47 47 47 47 47 47 47 47 48 49 48 48 48 48 48 48 48 49
				48 48 47 47 47 47 47 47 48 50 49 49 49 49 49 49 49 50
				47 47 47 47 47 46 46 47 48 49 48 48 48 48 48 48 48 49
				48 48 47 47 47 47 47 47 48 50 50 50 50 49 50 49 50 50
				48 47 47 47 47 47 47 47 48 49 48 48 48 48 48 48 48 49
				49 48 48 48 48 48 48 48 49 51 50 50 50 50 50 50 50 51
				48 47 47 47 47 47 47 47 48 48 47 48 48 47 48 48 48 49
				47 47 46 46 46 46 46 46 47 50 48 48 48 48 48 48 49 50
				48 47 47 47 47 47 47 47 48 49 48 48 48 48 48 48 48 50
				47 47 46 46 46 46 46 46 47 50 49 49 49 49 49 49 49 50
				47 47 47 47 47 47 47 47 48 49 48 48 48 48 48 48 48 48
				47 47 47 47 46 46 46 47 48 50 49 49 49 49 49 49 49 49
				47 47 47 47 47 47 47 47 48 48 48 48 48 47 48 48 48 48
				47 47 46 46 46 46 46 46 48 50 48 48 48 48 48 48 49 49
				47 47 47 47 47 47 47 47 48 48 47 47 47 47 47 47 48 48
				47 46 46 46 46 46 46 46 48 50 48 48 48 48 48 48 48 49
				>;

			PS_Config_Lmt_FW_Diff_P = <
				50 50 50 50 50 50 50 50 65535 65535 50 50 50 50 50 50 50 50
				50 50 50 50 50 50 50 50 50 50 50 50 50 50 50 50 50 50
				50 50 50 50 50 50 50 50 50 50 50 50 50 50 50 50 50 50
				50 50 50 50 50 50 50 50 50 50 50 50 50 50 50 50 50 50
				50 50 50 50 50 50 50 50 50 50 50 50 50 50 50 50 50 50
				50 50 50 50 50 50 50 50 50 50 50 50 50 50 50 50 50 50
				50 50 50 50 50 50 50 50 50 50 50 50 50 50 50 50 50 50
				50 50 50 50 50 50 50 50 50 50 50 50 50 50 50 50 50 50
				50 50 50 50 50 50 50 50 50 50 50 50 50 50 50 50 50 50
				50 50 50 50 50 50 50 50 50 50 50 50 50 50 50 50 50 50
				50 50 50 50 50 50 50 50 50 50 50 50 50 50 50 50 50 50
				50 50 50 50 50 50 50 50 50 50 50 50 50 50 50 50 50 50
				50 50 50 50 50 50 50 50 50 50 50 50 50 50 50 50 50 50
				50 50 50 50 50 50 50 50 50 50 50 50 50 50 50 50 50 50
				50 50 50 50 50 50 50 50 50 50 50 50 50 50 50 50 50 50
				50 50 50 50 50 50 50 50 50 50 50 50 50 50 50 50 50 50
				50 50 50 50 50 50 50 50 50 50 50 50 50 50 50 50 50 50
				50 50 50 50 50 50 50 50 50 50 50 50 50 50 50 50 50 50
				50 50 50 50 50 50 50 50 50 50 50 50 50 50 50 50 50 50
				50 50 50 50 50 50 50 50 50 50 50 50 50 50 50 50 50 50
				50 50 50 50 50 50 50 50 50 50 50 50 50 50 50 50 50 50
				50 50 50 50 50 50 50 50 50 50 50 50 50 50 50 50 50 50
				50 50 50 50 50 50 50 50 50 50 50 50 50 50 50 50 50 50
				50 50 50 50 50 50 50 50 50 50 50 50 50 50 50 50 50 50
				50 50 50 50 50 50 50 50 50 50 50 50 50 50 50 50 50 50
				50 50 50 50 50 50 50 50 50 50 50 50 50 50 50 50 50 50
				50 50 50 50 50 50 50 50 50 50 50 50 50 50 50 50 50 50
				50 50 50 50 50 50 50 50 50 50 50 50 50 50 50 50 50 50
				50 50 50 50 50 50 50 50 50 50 50 50 50 50 50 50 50 50
				50 50 50 50 50 50 50 50 50 50 50 50 50 50 50 50 50 50
				50 50 50 50 50 50 50 50 50 50 50 50 50 50 50 50 50 50
				50 50 50 50 50 50 50 50 50 50 50 50 50 50 50 50 50 50
				>;

			PS_Config_Lmt_FW_Diff_N = <
				(-50) (-50) (-50) (-50) (-50) (-50) (-50) (-50) (-65535) (-65535) (-50) (-50) (-50) (-50) (-50) (-50) (-50) (-50)
				(-50) (-50) (-50) (-50) (-50) (-50) (-50) (-50) (-50) (-50) (-50) (-50) (-50) (-50) (-50) (-50) (-50) (-50)
				(-50) (-50) (-50) (-50) (-50) (-50) (-50) (-50) (-50) (-50) (-50) (-50) (-50) (-50) (-50) (-50) (-50) (-50)
				(-50) (-50) (-50) (-50) (-50) (-50) (-50) (-50) (-50) (-50) (-50) (-50) (-50) (-50) (-50) (-50) (-50) (-50)
				(-50) (-50) (-50) (-50) (-50) (-50) (-50) (-50) (-50) (-50) (-50) (-50) (-50) (-50) (-50) (-50) (-50) (-50)
				(-50) (-50) (-50) (-50) (-50) (-50) (-50) (-50) (-50) (-50) (-50) (-50) (-50) (-50) (-50) (-50) (-50) (-50)
				(-50) (-50) (-50) (-50) (-50) (-50) (-50) (-50) (-50) (-50) (-50) (-50) (-50) (-50) (-50) (-50) (-50) (-50)
				(-50) (-50) (-50) (-50) (-50) (-50) (-50) (-50) (-50) (-50) (-50) (-50) (-50) (-50) (-50) (-50) (-50) (-50)
				(-50) (-50) (-50) (-50) (-50) (-50) (-50) (-50) (-50) (-50) (-50) (-50) (-50) (-50) (-50) (-50) (-50) (-50)
				(-50) (-50) (-50) (-50) (-50) (-50) (-50) (-50) (-50) (-50) (-50) (-50) (-50) (-50) (-50) (-50) (-50) (-50)
				(-50) (-50) (-50) (-50) (-50) (-50) (-50) (-50) (-50) (-50) (-50) (-50) (-50) (-50) (-50) (-50) (-50) (-50)
				(-50) (-50) (-50) (-50) (-50) (-50) (-50) (-50) (-50) (-50) (-50) (-50) (-50) (-50) (-50) (-50) (-50) (-50)
				(-50) (-50) (-50) (-50) (-50) (-50) (-50) (-50) (-50) (-50) (-50) (-50) (-50) (-50) (-50) (-50) (-50) (-50)
				(-50) (-50) (-50) (-50) (-50) (-50) (-50) (-50) (-50) (-50) (-50) (-50) (-50) (-50) (-50) (-50) (-50) (-50)
				(-50) (-50) (-50) (-50) (-50) (-50) (-50) (-50) (-50) (-50) (-50) (-50) (-50) (-50) (-50) (-50) (-50) (-50)
				(-50) (-50) (-50) (-50) (-50) (-50) (-50) (-50) (-50) (-50) (-50) (-50) (-50) (-50) (-50) (-50) (-50) (-50)
				(-50) (-50) (-50) (-50) (-50) (-50) (-50) (-50) (-50) (-50) (-50) (-50) (-50) (-50) (-50) (-50) (-50) (-50)
				(-50) (-50) (-50) (-50) (-50) (-50) (-50) (-50) (-50) (-50) (-50) (-50) (-50) (-50) (-50) (-50) (-50) (-50)
				(-50) (-50) (-50) (-50) (-50) (-50) (-50) (-50) (-50) (-50) (-50) (-50) (-50) (-50) (-50) (-50) (-50) (-50)
				(-50) (-50) (-50) (-50) (-50) (-50) (-50) (-50) (-50) (-50) (-50) (-50) (-50) (-50) (-50) (-50) (-50) (-50)
				(-50) (-50) (-50) (-50) (-50) (-50) (-50) (-50) (-50) (-50) (-50) (-50) (-50) (-50) (-50) (-50) (-50) (-50)
				(-50) (-50) (-50) (-50) (-50) (-50) (-50) (-50) (-50) (-50) (-50) (-50) (-50) (-50) (-50) (-50) (-50) (-50)
				(-50) (-50) (-50) (-50) (-50) (-50) (-50) (-50) (-50) (-50) (-50) (-50) (-50) (-50) (-50) (-50) (-50) (-50)
				(-50) (-50) (-50) (-50) (-50) (-50) (-50) (-50) (-50) (-50) (-50) (-50) (-50) (-50) (-50) (-50) (-50) (-50)
				(-50) (-50) (-50) (-50) (-50) (-50) (-50) (-50) (-50) (-50) (-50) (-50) (-50) (-50) (-50) (-50) (-50) (-50)
				(-50) (-50) (-50) (-50) (-50) (-50) (-50) (-50) (-50) (-50) (-50) (-50) (-50) (-50) (-50) (-50) (-50) (-50)
				(-50) (-50) (-50) (-50) (-50) (-50) (-50) (-50) (-50) (-50) (-50) (-50) (-50) (-50) (-50) (-50) (-50) (-50)
				(-50) (-50) (-50) (-50) (-50) (-50) (-50) (-50) (-50) (-50) (-50) (-50) (-50) (-50) (-50) (-50) (-50) (-50)
				(-50) (-50) (-50) (-50) (-50) (-50) (-50) (-50) (-50) (-50) (-50) (-50) (-50) (-50) (-50) (-50) (-50) (-50)
				(-50) (-50) (-50) (-50) (-50) (-50) (-50) (-50) (-50) (-50) (-50) (-50) (-50) (-50) (-50) (-50) (-50) (-50)
				(-50) (-50) (-50) (-50) (-50) (-50) (-50) (-50) (-50) (-50) (-50) (-50) (-50) (-50) (-50) (-50) (-50) (-50)
				(-50) (-50) (-50) (-50) (-50) (-50) (-50) (-50) (-50) (-50) (-50) (-50) (-50) (-50) (-50) (-50) (-50) (-50)
				>;

			PS_Config_Diff_Test_Frame = <50>;

			PS_Config_Lmt_LPWG_Rawdata_P = <
				2231 2245 2238 2235 2231 2228 2251 2241 65535 65535 2240 2237 2228 2241 2240 2234 2245 2238
				2255 2233 2251 2245 2249 2244 2235 2241 2227 2248 2244 2238 2230 2249 2228 2251 2230 2226
				2248 2244 2251 2233 2238 2240 2234 2242 2230 2209 2235 2240 2238 2231 2241 2262 2223 2234
				2242 2254 2219 2251 2245 2245 2237 2245 2244 2228 2231 2237 2247 2242 2245 2244 2247 2238
				2242 2244 2241 2241 2230 2247 2233 2242 2248 2226 2226 2233 2237 2230 2237 2231 2238 2242
				2235 2258 2248 2240 2254 2245 2245 2247 2234 2231 2245 2244 2242 2241 2241 2240 2237 2244
				2237 2248 2230 2233 2207 2248 2223 2210 2217 2237 2237 2248 2237 2235 2249 2237 2242 2233
				2258 2244 2233 2238 2254 2262 2255 2241 2254 2238 2245 2255 2248 2231 2227 2231 2242 2245
				2237 2241 2265 2254 2245 2247 2238 2251 2244 2248 2227 2223 2223 2245 2254 2238 2255 2230
				2241 2235 2233 2234 2244 2254 2244 2230 2231 2226 2226 2241 2238 2237 2249 2241 2258 2254
				2230 2233 2244 2238 2237 2268 2238 2242 2252 2242 2240 2238 2231 2238 2227 2231 2238 2228
				2245 2240 2240 2230 2233 2220 2231 2240 2238 2247 2235 2248 2238 2251 2241 2235 2247 2235
				2251 2230 2235 2231 2245 2245 2248 2240 2242 2242 2241 2245 2238 2240 2240 2249 2255 2245
				2237 2242 2251 2247 2242 2244 2240 2255 2255 2238 2251 2258 2256 2235 2241 2238 2255 2241
				2235 2228 2230 2230 2241 2244 2234 2231 2234 2252 2245 2240 2238 2240 2247 2230 2247 2227
				2242 2256 2256 2258 2251 2242 2237 2244 2244 2230 2242 2248 2226 2247 2248 2241 2234 2244
				2231 2247 2248 2251 2245 2249 2245 2258 2242 2245 2249 2240 2237 2226 2234 2245 2235 2242
				2231 2248 2231 2234 2235 2245 2249 2256 2237 2247 2244 2249 2234 2248 2238 2249 2245 2254
				2248 2241 2254 2248 2242 2242 2252 2247 2255 2245 2237 2240 2248 2228 2231 2237 2233 2256
				2266 2245 2235 2241 2247 2248 2247 2252 2245 2237 2247 2251 2244 2262 2249 2237 2249 2235
				2220 2233 2237 2228 2233 2230 2224 2233 2231 2249 2226 2235 2237 2237 2242 2237 2244 2234
				2237 2230 2238 2238 2226 2237 2235 2234 2237 2238 2244 2251 2244 2251 2249 2247 2226 2241
				2263 2214 2262 2231 2255 2262 2254 2248 2248 2247 2258 2263 2266 2245 2262 2268 2234 2251
				2245 2241 2235 2241 2248 2255 2255 2244 2244 2252 2259 2254 2249 2261 2247 2251 2233 2242
				2258 2244 2251 2265 2238 2240 2233 2238 2247 2231 2247 2227 2226 2231 2227 2223 2249 2227
				2251 2233 2242 2252 2228 2230 2230 2235 2235 2247 2237 2240 2228 2242 2247 2249 2245 2248
				2221 2241 2244 2234 2241 2240 2233 2240 2235 2238 2249 2251 2254 2240 2251 2242 2241 2244
				2242 2256 2242 2244 2224 2242 2227 2223 2234 2226 2241 2251 2249 2228 2245 2265 2237 2249
				2240 2227 2226 2226 2244 2242 2242 2235 2234 2266 2248 2252 2251 2240 2251 2245 2234 2231
				2238 2241 2234 2237 2245 2244 2238 2233 2242 2244 2245 2245 2240 2238 2241 2235 2248 2241
				2244 2252 2242 2245 2228 2226 2224 2252 2247 2230 2233 2228 2230 2234 2228 2238 2241 2252
				2231 2238 2242 2247 2245 2244 2238 2244 2242 2245 2242 2259 2249 2227 2242 2230 2241 2252
				>;

			PS_Config_Lmt_LPWG_Rawdata_N = <
				956 962 959 958 956 955 964 960 (-65535) (-65535) 960 958 955 960 960 957 962 959
				966 957 964 962 964 961 958 960 954 963 961 959 955 964 955 964 955 954
				963 961 964 957 959 960 957 961 955 946 958 960 959 956 960 969 952 957
				961 966 951 964 962 962 958 962 961 955 956 958 963 961 962 961 963 959
				961 961 960 960 955 963 957 961 963 954 954 957 958 955 958 956 959 961
				958 967 963 960 966 962 962 963 957 956 962 961 961 960 960 960 958 961
				958 963 955 957 946 963 952 947 950 958 958 963 958 958 964 958 961 957
				967 961 957 959 966 969 966 960 966 959 962 966 963 956 954 956 961 962
				958 960 970 966 962 963 959 964 961 963 954 952 952 962 966 959 966 955
				960 958 957 957 961 966 961 955 956 954 954 960 959 958 964 960 967 966
				955 957 961 959 958 972 959 961 965 961 960 959 956 959 954 956 959 955
				962 960 960 955 957 951 956 960 959 963 958 963 959 964 960 958 963 958
				964 955 958 956 962 962 963 960 961 961 960 962 959 960 960 964 966 962
				958 961 964 963 961 961 960 966 966 959 964 967 967 958 960 959 966 960
				958 955 955 955 960 961 957 956 957 965 962 960 959 960 963 955 963 954
				961 967 967 967 964 961 958 961 961 955 961 963 954 963 963 960 957 961
				956 963 963 964 962 964 962 967 961 962 964 960 958 954 957 962 958 961
				956 963 956 957 958 962 964 967 958 963 961 964 957 963 959 964 962 966
				963 960 966 963 961 961 965 963 966 962 958 960 963 955 956 958 957 967
				971 962 958 960 963 963 963 965 962 958 963 964 961 969 964 958 964 958
				951 957 958 955 957 955 953 957 956 964 954 958 958 958 961 958 961 957
				958 955 959 959 954 958 958 957 958 959 961 964 961 964 964 963 954 960
				970 949 969 956 966 969 966 963 963 963 967 970 971 962 969 972 957 964
				962 960 958 960 963 966 966 961 961 965 968 966 964 969 963 964 957 961
				967 961 964 970 959 960 957 959 963 956 963 954 954 956 954 952 964 954
				964 957 961 965 955 955 955 958 958 963 958 960 955 961 963 964 962 963
				952 960 961 957 960 960 957 960 958 959 964 964 966 960 964 961 960 961
				961 967 961 961 953 961 954 952 957 954 960 964 964 955 962 970 958 964
				960 954 954 954 961 961 961 958 957 971 963 965 964 960 964 962 957 956
				959 960 957 958 962 961 959 957 961 961 962 962 960 959 960 958 963 960
				961 965 961 962 955 954 953 965 963 955 957 955 955 957 955 959 960 965
				956 959 961 963 962 961 959 961 961 962 961 968 964 954 961 955 960 965
				>;

			PS_Config_Lmt_LPWG_Diff_P = <
				60 60 60 60 60 60 60 60 65535 65535 60 60 60 60 60 60 60 60
				60 60 60 60 60 60 60 60 60 60 60 60 60 60 60 60 60 60
				60 60 60 60 60 60 60 60 60 60 60 60 60 60 60 60 60 60
				60 60 60 60 60 60 60 60 60 60 60 60 60 60 60 60 60 60
				60 60 60 60 60 60 60 60 60 60 60 60 60 60 60 60 60 60
				60 60 60 60 60 60 60 60 60 60 60 60 60 60 60 60 60 60
				60 60 60 60 60 60 60 60 60 60 60 60 60 60 60 60 60 60
				60 60 60 60 60 60 60 60 60 60 60 60 60 60 60 60 60 60
				60 60 60 60 60 60 60 60 60 60 60 60 60 60 60 60 60 60
				60 60 60 60 60 60 60 60 60 60 60 60 60 60 60 60 60 60
				60 60 60 60 60 60 60 60 60 60 60 60 60 60 60 60 60 60
				60 60 60 60 60 60 60 60 60 60 60 60 60 60 60 60 60 60
				60 60 60 60 60 60 60 60 60 60 60 60 60 60 60 60 60 60
				60 60 60 60 60 60 60 60 60 60 60 60 60 60 60 60 60 60
				60 60 60 60 60 60 60 60 60 60 60 60 60 60 60 60 60 60
				60 60 60 60 60 60 60 60 60 60 60 60 60 60 60 60 60 60
				60 60 60 60 60 60 60 60 60 60 60 60 60 60 60 60 60 60
				60 60 60 60 60 60 60 60 60 60 60 60 60 60 60 60 60 60
				60 60 60 60 60 60 60 60 60 60 60 60 60 60 60 60 60 60
				60 60 60 60 60 60 60 60 60 60 60 60 60 60 60 60 60 60
				60 60 60 60 60 60 60 60 60 60 60 60 60 60 60 60 60 60
				60 60 60 60 60 60 60 60 60 60 60 60 60 60 60 60 60 60
				60 60 60 60 60 60 60 60 60 60 60 60 60 60 60 60 60 60
				60 60 60 60 60 60 60 60 60 60 60 60 60 60 60 60 60 60
				60 60 60 60 60 60 60 60 60 60 60 60 60 60 60 60 60 60
				60 60 60 60 60 60 60 60 60 60 60 60 60 60 60 60 60 60
				60 60 60 60 60 60 60 60 60 60 60 60 60 60 60 60 60 60
				60 60 60 60 60 60 60 60 60 60 60 60 60 60 60 60 60 60
				60 60 60 60 60 60 60 60 60 60 60 60 60 60 60 60 60 60
				60 60 60 60 60 60 60 60 60 60 60 60 60 60 60 60 60 60
				60 60 60 60 60 60 60 60 60 60 60 60 60 60 60 60 60 60
				60 60 60 60 60 60 60 60 60 60 60 60 60 60 60 60 60 60
				>;

			PS_Config_Lmt_LPWG_Diff_N = <
				(-60) (-60) (-60) (-60) (-60) (-60) (-60) (-60) (-65535) (-65535) (-60) (-60) (-60) (-60) (-60) (-60) (-60) (-60)
				(-60) (-60) (-60) (-60) (-60) (-60) (-60) (-60) (-60) (-60) (-60) (-60) (-60) (-60) (-60) (-60) (-60) (-60)
				(-60) (-60) (-60) (-60) (-60) (-60) (-60) (-60) (-60) (-60) (-60) (-60) (-60) (-60) (-60) (-60) (-60) (-60)
				(-60) (-60) (-60) (-60) (-60) (-60) (-60) (-60) (-60) (-60) (-60) (-60) (-60) (-60) (-60) (-60) (-60) (-60)
				(-60) (-60) (-60) (-60) (-60) (-60) (-60) (-60) (-60) (-60) (-60) (-60) (-60) (-60) (-60) (-60) (-60) (-60)
				(-60) (-60) (-60) (-60) (-60) (-60) (-60) (-60) (-60) (-60) (-60) (-60) (-60) (-60) (-60) (-60) (-60) (-60)
				(-60) (-60) (-60) (-60) (-60) (-60) (-60) (-60) (-60) (-60) (-60) (-60) (-60) (-60) (-60) (-60) (-60) (-60)
				(-60) (-60) (-60) (-60) (-60) (-60) (-60) (-60) (-60) (-60) (-60) (-60) (-60) (-60) (-60) (-60) (-60) (-60)
				(-60) (-60) (-60) (-60) (-60) (-60) (-60) (-60) (-60) (-60) (-60) (-60) (-60) (-60) (-60) (-60) (-60) (-60)
				(-60) (-60) (-60) (-60) (-60) (-60) (-60) (-60) (-60) (-60) (-60) (-60) (-60) (-60) (-60) (-60) (-60) (-60)
				(-60) (-60) (-60) (-60) (-60) (-60) (-60) (-60) (-60) (-60) (-60) (-60) (-60) (-60) (-60) (-60) (-60) (-60)
				(-60) (-60) (-60) (-60) (-60) (-60) (-60) (-60) (-60) (-60) (-60) (-60) (-60) (-60) (-60) (-60) (-60) (-60)
				(-60) (-60) (-60) (-60) (-60) (-60) (-60) (-60) (-60) (-60) (-60) (-60) (-60) (-60) (-60) (-60) (-60) (-60)
				(-60) (-60) (-60) (-60) (-60) (-60) (-60) (-60) (-60) (-60) (-60) (-60) (-60) (-60) (-60) (-60) (-60) (-60)
				(-60) (-60) (-60) (-60) (-60) (-60) (-60) (-60) (-60) (-60) (-60) (-60) (-60) (-60) (-60) (-60) (-60) (-60)
				(-60) (-60) (-60) (-60) (-60) (-60) (-60) (-60) (-60) (-60) (-60) (-60) (-60) (-60) (-60) (-60) (-60) (-60)
				(-60) (-60) (-60) (-60) (-60) (-60) (-60) (-60) (-60) (-60) (-60) (-60) (-60) (-60) (-60) (-60) (-60) (-60)
				(-60) (-60) (-60) (-60) (-60) (-60) (-60) (-60) (-60) (-60) (-60) (-60) (-60) (-60) (-60) (-60) (-60) (-60)
				(-60) (-60) (-60) (-60) (-60) (-60) (-60) (-60) (-60) (-60) (-60) (-60) (-60) (-60) (-60) (-60) (-60) (-60)
				(-60) (-60) (-60) (-60) (-60) (-60) (-60) (-60) (-60) (-60) (-60) (-60) (-60) (-60) (-60) (-60) (-60) (-60)
				(-60) (-60) (-60) (-60) (-60) (-60) (-60) (-60) (-60) (-60) (-60) (-60) (-60) (-60) (-60) (-60) (-60) (-60)
				(-60) (-60) (-60) (-60) (-60) (-60) (-60) (-60) (-60) (-60) (-60) (-60) (-60) (-60) (-60) (-60) (-60) (-60)
				(-60) (-60) (-60) (-60) (-60) (-60) (-60) (-60) (-60) (-60) (-60) (-60) (-60) (-60) (-60) (-60) (-60) (-60)
				(-60) (-60) (-60) (-60) (-60) (-60) (-60) (-60) (-60) (-60) (-60) (-60) (-60) (-60) (-60) (-60) (-60) (-60)
				(-60) (-60) (-60) (-60) (-60) (-60) (-60) (-60) (-60) (-60) (-60) (-60) (-60) (-60) (-60) (-60) (-60) (-60)
				(-60) (-60) (-60) (-60) (-60) (-60) (-60) (-60) (-60) (-60) (-60) (-60) (-60) (-60) (-60) (-60) (-60) (-60)
				(-60) (-60) (-60) (-60) (-60) (-60) (-60) (-60) (-60) (-60) (-60) (-60) (-60) (-60) (-60) (-60) (-60) (-60)
				(-60) (-60) (-60) (-60) (-60) (-60) (-60) (-60) (-60) (-60) (-60) (-60) (-60) (-60) (-60) (-60) (-60) (-60)
				(-60) (-60) (-60) (-60) (-60) (-60) (-60) (-60) (-60) (-60) (-60) (-60) (-60) (-60) (-60) (-60) (-60) (-60)
				(-60) (-60) (-60) (-60) (-60) (-60) (-60) (-60) (-60) (-60) (-60) (-60) (-60) (-60) (-60) (-60) (-60) (-60)
				(-60) (-60) (-60) (-60) (-60) (-60) (-60) (-60) (-60) (-60) (-60) (-60) (-60) (-60) (-60) (-60) (-60) (-60)
				(-60) (-60) (-60) (-60) (-60) (-60) (-60) (-60) (-60) (-60) (-60) (-60) (-60) (-60) (-60) (-60) (-60) (-60)
				>;
		}; /* novatek-mp-criteria-hlt */
    };
};
//#endif
/* TOUCH end */

/* CONSYS GPIO standardization */
&pio {
	consys_pins_default: consys_default {
	};
	gpslna_pins_init: gpslna@0 {
		pins_cmd_dat {
			pinmux = <PINMUX_GPIO91__FUNC_GPIO91>;
			slew-rate = <0>;
			bias-disable;
			output-low;
		};
	};
	gpslna_pins_oh: gpslna@1 {
		pins_cmd_dat {
			pinmux = <PINMUX_GPIO91__FUNC_GPIO91>;
			slew-rate = <1>;
			output-high;
		};
	};
	gpslna_pins_ol: gpslna@2 {
		pins_cmd_dat {
			pinmux = <PINMUX_GPIO91__FUNC_GPIO91>;
			slew-rate = <1>;
			output-low;
		};
	};
};
&consys {
	pinctrl-names = "default", "gps_lna_state_init",
		"gps_lna_state_oh", "gps_lna_state_ol";
	pinctrl-0 = <&consys_pins_default>;
	pinctrl-1 = <&gpslna_pins_init>;
	pinctrl-2 = <&gpslna_pins_oh>;
	pinctrl-3 = <&gpslna_pins_ol>;
	status = "okay";
};
/* CONSYS end */

/* accdet start */
&accdet {
        /*#ifdef ODM_WT_EDIT*/
        /*Shouxing.Tang@ODM_WT.MM.Audiodriver.accdet, 2020/4/4, change hs mic bias1 2.7v for 206A1*/
	accdet-mic-vol = <7>;
        /*#endif*/
	headset-mode-setting = <0x500 0x500 1 0x1f0 0x800 0x800 0x20 0x44>;
	accdet-plugout-debounce = <1>;
	accdet-mic-mode = <1>;
	headset-eint-level-pol = <8>;
	headset-three-key-threshold = <0 55 130 400>;
	headset-three-key-threshold-CDD = <0 121 192 600>;
	headset-four-key-threshold = <0 58 121 192 400>;
	pinctrl-names = "default", "state_eint_as_int";
	pinctrl-0 = <&accdet_pins_default>;
	pinctrl-1 = <&accdet_pins_eint_as_int>;
	status = "okay";
};
&pio {
	accdet_pins_default: accdetdefault {
	};
	accdet_pins_eint_as_int: accdeteint@0 {
		pins_cmd_dat {
			pinmux = <PINMUX_GPIO9__FUNC_GPIO9>;
			slew-rate = <0>;
			bias-disable;
		};
	};
};
/* accdet end */

//#ifdef ODM_WT_EDIT
//#Zhaoliang.Shi@ODM_WT.BSP.Fingerprint.Basic, 2018/9/25, Add for fingerprint driver
/* FINGERPRINT start */
&spi1 {
	#address-cells = <1>;
	#size-cells = <0>;
	egis_spi@0 {
		compatible = "mediatek,fingerspi-fp";
		reg = <0>;
		spi-max-frequency = <8000000>;
		netlink-event = <30>;
		status = "okay";
	};
};

&egis_fp {
	pinctrl-names = "rst-high", "rst-low";
	pinctrl-0 = <&fingerfp_rst_high>;
	pinctrl-1 = <&fingerfp_rst_low>;
 	status = "okay";
 };

&pio {
	fingerfp_rst_high: state_reset_high {
		pins_cmd_dat {
			pinmux = <PINMUX_GPIO7__FUNC_GPIO7>;
			slew-rate = <1>;
			output-high;
		};
	};
	fingerfp_rst_low: state_reset_low {
		pins_cmd_dat {
			pinmux = <PINMUX_GPIO7__FUNC_GPIO7>;
			slew-rate = <1>;
			output-low;
		};
	};
};

&oppo_fp_common {
	oppo,fp-id0 = <&pio 166 0x00>;
	pinctrl-names = "gpio_id0_up","gpio_id0_down";
	pinctrl-0 = <&gpio_id0_up>;
	pinctrl-1 = <&gpio_id0_down>;
	status = "okay";
 };

&pio {
	gpio_id0_up: gpio_id0_up {
		pins_cmd_dat {
			pinmux = <PINMUX_GPIO166__FUNC_GPIO166>;
			slew-rate = <0>;
			bias-pull-up;
			input-enable;
		};
	};
	gpio_id0_down: gpio_id0_down {
		pins_cmd_dat {
			pinmux = <PINMUX_GPIO166__FUNC_GPIO166>;
			slew-rate = <0>;
			bias-pull-down;
			input-enable;
		};
	};
};

&fpsensor_finger {
	interrupt-parent = <&gic>;
	interrupts = <5 IRQ_TYPE_EDGE_RISING>;
	debounce = <2 0>;
	pinctrl-names = "fpsensor_finger_rst_low","fpsensor_finger_rst_high";
	pinctrl-0 = <&fpsensor_finger_rst_mode_en0>;
	pinctrl-1 = <&fpsensor_finger_rst_mode_en1>;
	status = "okay";
};

&pio {
	fpsensor_finger_rst_mode_en0: fpsensor_finger_rst_mode_en0 {
		pins_cmd_dat {
			pinmux = <PINMUX_GPIO7__FUNC_GPIO7>;
			slew-rate = <1>;
			output-low;
		};
	};
	fpsensor_finger_rst_mode_en1: fpsensor_finger_rst_mode_en1 {
		pins_cmd_dat {
			pinmux = <PINMUX_GPIO7__FUNC_GPIO7>;
			slew-rate = <1>;
			output-high;
		};
	};
};

/* FINGERPRINT end */
//#endif /*ODM_WT_EDIT*/


/* IRTX GPIO end */
&irtx_pwm {
	pinctrl-names = "irtx_gpio_led_default", "irtx_gpio_led_set";
	pinctrl-0 = <&irtx_gpio_led_default>;
	pinctrl-1 = <&irtx_gpio_led_set>;
	status = "okay";
};
&pio {
	irtx_gpio_led_default:irtx_gpio_led_def@gpio90 {
	};

	irtx_gpio_led_set:irtx_gpio_led_set@gpio90 {
	};
};
/* IRTX GPIO Settings -End */

/* AUDIO GPIO standardization */
&audgpio {
	pinctrl-names = "aud_clk_mosi_off",
			"aud_clk_mosi_on",
			"aud_clk_miso_off",
			"aud_clk_miso_on",
			"aud_dat_mosi_off",
			"aud_dat_mosi_on",
			"aud_dat_miso_off",
			"aud_dat_miso_on",
			"aud_smartpa_off",
			"aud_smartpa_on";
	pinctrl-0 = <&aud_clk_mosi_off>;
	pinctrl-1 = <&aud_clk_mosi_on>;
	pinctrl-2 = <&aud_clk_miso_off>;
	pinctrl-3 = <&aud_clk_miso_on>;
	pinctrl-4 = <&aud_dat_mosi_off>;
	pinctrl-5 = <&aud_dat_mosi_on>;
	pinctrl-6 = <&aud_dat_miso_off>;
	pinctrl-7 = <&aud_dat_miso_on>;
	pinctrl-8 = <&aud_pins_smartpa_off>;
	pinctrl-9 = <&aud_pins_smartpa_on>;
	status = "okay";
};

&pio {
	aud_clk_mosi_off: aud_clk_mosi_off {
		pins_cmd0_dat {
			pinmux = <PINMUX_GPIO136__FUNC_GPIO136>;
		};
	};

	aud_clk_mosi_on: aud_clk_mosi_on {
		pins_cmd0_dat {
			pinmux = <PINMUX_GPIO136__FUNC_AUD_CLK_MOSI>;
		};
	};

	aud_clk_miso_off: aud_clk_miso_off {
		pins_cmd0_dat {
			pinmux = <PINMUX_GPIO140__FUNC_GPIO140>;
		};
	};

	aud_clk_miso_on: aud_clk_miso_on {
		pins_cmd0_dat {
			pinmux = <PINMUX_GPIO140__FUNC_AUD_CLK_MISO>;
		};
	};

	aud_dat_mosi_off: aud_dat_mosi_off {
		pins_cmd1_dat {
			pinmux = <PINMUX_GPIO138__FUNC_GPIO138>;
			input-enable;
			slew-rate = <0>;
			bias-disable;
		};
		pins_cmd2_dat {
			pinmux = <PINMUX_GPIO139__FUNC_GPIO139>;
			input-enable;
			slew-rate = <0>;
			bias-disable;
		};
	};

	aud_dat_mosi_on: aud_dat_mosi_on {
		pins_cmd1_dat {
			pinmux = <PINMUX_GPIO138__FUNC_AUD_DAT_MOSI0>;
		};
		pins_cmd2_dat {
			pinmux = <PINMUX_GPIO139__FUNC_AUD_DAT_MOSI1>;
		};
	};

	aud_dat_miso_off: aud_dat_miso_off {
		pins_cmd1_dat {
			pinmux = <PINMUX_GPIO142__FUNC_GPIO142>;
			input-enable;
			slew-rate = <0>;
			bias-disable;
		};
		pins_cmd2_dat {
			pinmux = <PINMUX_GPIO143__FUNC_GPIO143>;
			input-enable;
			slew-rate = <0>;
			bias-disable;
		};
	};

	aud_dat_miso_on: aud_dat_miso_on {
		pins_cmd1_dat {
			pinmux = <PINMUX_GPIO142__FUNC_AUD_DAT_MISO0>;
		};
		pins_cmd2_dat {
			pinmux = <PINMUX_GPIO143__FUNC_AUD_DAT_MISO1>;
		};
	};

	aud_pins_smartpa_off: aud_pins_smartpa_off {
		pins_cmd0_dat {
			pinmux = <PINMUX_GPIO17__FUNC_GPIO17>;
		};
		pins_cmd1_dat {
			pinmux = <PINMUX_GPIO18__FUNC_GPIO18>;
		};
		pins_cmd2_dat {
			pinmux = <PINMUX_GPIO19__FUNC_GPIO19>;
		};
		pins_cmd3_dat {
			pinmux = <PINMUX_GPIO20__FUNC_GPIO20>;
		};
	};

	aud_pins_smartpa_on: aud_pins_smartpa_on {
		pins_cmd0_dat {
			pinmux = <PINMUX_GPIO17__FUNC_I2S0_DI>;
		};
		pins_cmd1_dat {
			pinmux = <PINMUX_GPIO18__FUNC_I2S3_BCK>;
		};
		pins_cmd2_dat {
			pinmux = <PINMUX_GPIO19__FUNC_I2S3_LRCK>;
		};
		pins_cmd3_dat {
			pinmux = <PINMUX_GPIO20__FUNC_I2S3_DO>;
		};
	};
};
/* AUDIO end */

&mt6370_typec {
	mt6370pd,intr_gpio_num = <41>; /* direct defined GPIO num */
	mt6370pd,intr_gpio = <&pio 41 0x0>;
};

//#ifdef ODM_WT_EDIT
#include "rt9471_single.dtsi"
#include "bq25910.dtsi"
#include "bq2589x.dtsi"
//#endif /*ODM_WT_EDIT*/
/* Wu.Weihong@ODM_WT.MM.Display.Lcd, 2020/3/23, LCD bringup */
/* DISPSYS GPIO standardization */
&mtkfb {
        pinctrl-names = "lcm_rst_out0_gpio", "lcm_rst_out1_gpio", "lcd_bias_enp0_gpio", "lcd_bias_enp1_gpio",
			"lcd_bias_enn0_gpio", "lcd_bias_enn1_gpio", "lcd_vddio18_en0_gpio", "lcd_vddio18_en1_gpio";

	pinctrl-0 = <&mtkfb_pins_lcm_reset0>;
	pinctrl-1 = <&mtkfb_pins_lcm_reset1>;
	pinctrl-2 = <&mtkfb_pins_lcd_bias_enp0>;
	pinctrl-3 = <&mtkfb_pins_lcd_bias_enp1>;
	pinctrl-4 = <&mtkfb_pins_lcd_bias_enn0>;
	pinctrl-5 = <&mtkfb_pins_lcd_bias_enn1>;
	//pinctrl-6 = <&mtkfb_pins_lcd_vddio18_en0>;
	//pinctrl-7 = <&mtkfb_pins_lcd_vddio18_en1>;
        status = "okay";
};

&pio {
	mtkfb_pins_lcm_reset0: lcm_rst_out0_gpio {
			pins_cmd_dat {
					pinmux = <PINMUX_GPIO45__FUNC_GPIO45>;
					slew-rate = <1>;
					output-low;
			};
	};
	mtkfb_pins_lcm_reset1: lcm_rst_out1_gpio {
			pins_cmd_dat {
					pinmux = <PINMUX_GPIO45__FUNC_GPIO45>;
					slew-rate = <1>;
					output-high;
			};
	};

	mtkfb_pins_lcd_bias_enp0: lcd_bias_enp0_gpio {
                pins_cmd_dat {
                        pinmux = <PINMUX_GPIO150__FUNC_GPIO150>;
                        slew-rate = <1>;
                        output-low;
                };
        };
	mtkfb_pins_lcd_bias_enp1: lcd_bias_enp1_gpio {
                pins_cmd_dat {
                        pinmux = <PINMUX_GPIO150__FUNC_GPIO150>;
                        slew-rate = <1>;
                        output-high;
                };
        };

	mtkfb_pins_lcd_bias_enn0: lcd_bias_enn0_gpio {
                pins_cmd_dat {
                        pinmux = <PINMUX_GPIO151__FUNC_GPIO151>;
                        slew-rate = <1>;
                        output-low;
                };
        };
	mtkfb_pins_lcd_bias_enn1: lcd_bias_enn1_gpio {
                pins_cmd_dat {
                        pinmux = <PINMUX_GPIO151__FUNC_GPIO151>;
                        slew-rate = <1>;
                        output-high;
                };
        };
};
/* Wu.Weihong@ODM_WT.MM.Display.Lcd, 2020/3/23, LCD bringup */
#include <oppo6765/cust.dtsi>
#include "cust_mt6765_camera.dtsi"
/*End of this file, DO NOT ADD ANYTHING HERE*/
